VERSION ""

NS_ :

BS_:

BU_: ZD VCU TPMS RESERVED_FRAMES RCM RAC PCU PAS ESP DiagnosticTester CHG CDCM BMS ABS

BO_ 1323 Reserved_148: 8 RESERVED_FRAMES

BO_ 1322 Reserved_147: 8 RESERVED_FRAMES

BO_ 1321 Reserved_146: 8 RESERVED_FRAMES

BO_ 1320 Reserved_145: 8 RESERVED_FRAMES

BO_ 1319 Reserved_144: 8 RESERVED_FRAMES

BO_ 1318 Reserved_143: 8 RESERVED_FRAMES

BO_ 1317 Reserved_142: 8 RESERVED_FRAMES

BO_ 1316 Reserved_141: 8 RESERVED_FRAMES

BO_ 1315 Reserved_140: 8 RESERVED_FRAMES

BO_ 779 Reserved_14: 8 RESERVED_FRAMES

BO_ 1314 Reserved_139: 8 RESERVED_FRAMES

BO_ 1313 Reserved_138: 8 RESERVED_FRAMES

BO_ 1312 Reserved_137: 8 RESERVED_FRAMES

BO_ 1311 Reserved_136: 8 RESERVED_FRAMES

BO_ 1310 Reserved_135: 8 RESERVED_FRAMES

BO_ 1309 Reserved_134: 8 RESERVED_FRAMES

BO_ 1308 Reserved_133: 8 RESERVED_FRAMES

BO_ 1307 Reserved_132: 8 RESERVED_FRAMES

BO_ 1306 Reserved_131: 8 RESERVED_FRAMES

BO_ 1305 Reserved_130: 8 RESERVED_FRAMES

BO_ 1304 Reserved_129: 8 RESERVED_FRAMES

BO_ 1303 Reserved_128: 8 RESERVED_FRAMES

BO_ 1302 Reserved_127: 8 RESERVED_FRAMES

BO_ 1301 Reserved_126: 8 RESERVED_FRAMES

BO_ 1300 Reserved_125: 8 RESERVED_FRAMES

BO_ 1299 Reserved_124: 8 RESERVED_FRAMES

BO_ 1298 Reserved_123: 8 RESERVED_FRAMES

BO_ 1297 Reserved_122: 8 RESERVED_FRAMES

BO_ 1296 Reserved_121: 8 RESERVED_FRAMES

BO_ 1295 Reserved_120: 8 RESERVED_FRAMES

BO_ 1294 Reserved_119: 8 RESERVED_FRAMES

BO_ 1293 Reserved_118: 8 RESERVED_FRAMES

BO_ 1292 Reserved_117: 8 RESERVED_FRAMES

BO_ 1291 Reserved_116: 8 RESERVED_FRAMES

BO_ 1290 Reserved_115: 8 RESERVED_FRAMES

BO_ 1289 Reserved_114: 8 RESERVED_FRAMES

BO_ 1288 Reserved_113: 8 RESERVED_FRAMES

BO_ 1287 Reserved_112: 8 RESERVED_FRAMES

BO_ 1286 Reserved_111: 8 RESERVED_FRAMES

BO_ 1285 Reserved_110: 8 RESERVED_FRAMES

BO_ 1284 Reserved_109: 8 RESERVED_FRAMES

BO_ 1283 Reserved_108: 8 RESERVED_FRAMES

BO_ 1282 Reserved_107: 8 RESERVED_FRAMES

BO_ 1281 Reserved_106: 8 RESERVED_FRAMES

BO_ 1280 Reserved_105: 8 RESERVED_FRAMES

BO_ 1909 Reserved_103: 8 RESERVED_FRAMES

BO_ 1906 Reserved_102: 8 RESERVED_FRAMES

BO_ 146 Reserved_101: 8 RESERVED_FRAMES

BO_ 520 Reserved_100: 8 RESERVED_FRAMES

BO_ 128 Reserved_1: 8 RESERVED_FRAMES

BO_ 1120 RCM_Status: 8 RCM
 SG_ RIL_Request : 39|2@0+ (1,0) [0|3] ""  RAC

BO_ 35 RCM_Event: 1 RCM
 SG_ RCM_FuelCutOff : 6|2@0+ (1,0) [0|3] ""  PCU,RAC,BMS
 SG_ RCM_EventNotification : 7|1@0+ (1,0) [0|1] ""  PCU,BMS,RAC

BO_ 1664 RCM_Diagnostic_Priv: 8 RCM

BO_ 1855 RCM_Diagnostic: 8 RCM

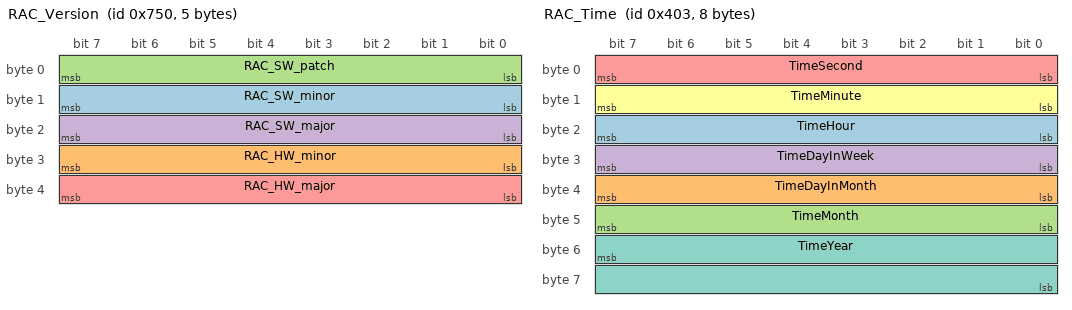
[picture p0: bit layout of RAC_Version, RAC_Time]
BO_ 1872 RAC_Version: 5 RAC
 SG_ RAC_SW_minor : 15|8@0+ (1,0) [0|255] "" Vector__XXX
 SG_ RAC_HW_minor : 31|8@0+ (1,0) [0|255] "" Vector__XXX
 SG_ RAC_SW_patch : 7|8@0+ (1,0) [0|255] "" Vector__XXX
 SG_ RAC_SW_major : 23|8@0+ (1,0) [0|255] "" Vector__XXX
 SG_ RAC_HW_major : 39|8@0+ (1,0) [0|255] "" Vector__XXX

BO_ 1874 RAC_VIN: 8 RAC
 SG_ VIN_Data : 15|48@0+ (1,0) [0|2.8147497671E+014] "" Vector__XXX
 SG_ VIN_Index : 7|8@0+ (1,0) [0|255] "" Vector__XXX

BO_ 1027 RAC_Time: 8 RAC
 SG_ TimeHour : 23|8@0+ (1,0) [0|255] "h" Vector__XXX
 SG_ TimeDayInMonth : 39|8@0+ (1,0) [0|255] "day" Vector__XXX
 SG_ TimeMonth : 47|8@0+ (1,0) [0|255] "Month" Vector__XXX
 SG_ TimeDayInWeek : 31|8@0+ (1,0) [0|255] "" Vector__XXX
 SG_ TimeSecond : 7|8@0+ (1,0) [0|255] "s" Vector__XXX
 SG_ TimeMinute : 15|8@0+ (1,0) [0|255] "min" Vector__XXX
 SG_ TimeYear : 55|16@0+ (1,0) [0|65535] "Year" Vector__XXX

BO_ 1025 RAC_Status: 8 RAC
 SG_ MemoryManagementStatus : 51|1@0+ (1,0) [0|1] "" Vector__XXX
 SG_ AirbagLampDriver : 23|2@0+ (1,0) [0|3] "" Vector__XXX
 SG_ HelpDeskLampStatus : 43|3@0+ (1,0) [0|7] "" Vector__XXX
 SG_ PhoneCallStatus : 36|3@0+ (1,0) [0|7] "" Vector__XXX
 SG_ GPRSStatus : 14|3@0+ (1,0) [0|7] "" Vector__XXX
 SG_ InCommunication : 50|1@0+ (1,0) [0|1] "" Vector__XXX
 SG_ GPSAntennaStatus : 21|2@0+ (1,0) [0|3] "" Vector__XXX
 SG_ CarState : 39|2@0+ (1,0) [0|3] "" Vector__XXX
 SG_ BluetoothConnection : 33|1@0+ (1,0) [0|1] "" Vector__XXX
 SG_ BluetoothStatus : 32|1@0+ (1,0) [0|1] "" Vector__XXX
 SG_ GPSStatus : 19|4@0+ (1,0) [0|15] "" Vector__XXX
 SG_ ContactKey : 0|1@0+ (1,0) [0|1] "" Vector__XXX
 SG_ SIMCardStatus : 8|1@0+ (1,0) [0|1] "" Vector__XXX
 SG_ HelpDeskRequest : 37|1@0+ (1,0) [0|1] "" Vector__XXX
 SG_ GSMStatus : 11|3@0+ (1,0) [0|7] "" Vector__XXX
 SG_ GPSModuleStatus : 53|2@0+ (1,0) [0|3] "" Vector__XXX
 SG_ CSQQuality : 28|5@0+ (1,0) [0|31] "" Vector__XXX
 SG_ ConnectedToServer : 15|1@0+ (1,0) [0|1] "" Vector__XXX
 SG_ AirbagLampStatus : 6|2@0+ (1,0) [0|3] "" Vector__XXX
 SG_ HelpDeskButtonStatus : 1|1@0+ (1,0) [0|1] "" Vector__XXX
 SG_ GSMModuleStatus : 55|2@0+ (1,0) [0|3] "" Vector__XXX
 SG_ AssistNumberProgrammed : 7|1@0+ (1,0) [0|1] "" Vector__XXX
 SG_ EPOStatus : 4|1@0+ (1,0) [0|1] "" Vector__XXX
 SG_ CrashEvent : 3|1@0+ (1,0) [0|1] "" Vector__XXX
 SG_ GPSSatellites : 47|4@0+ (1,0) [0|15] "" Vector__XXX
 SG_ SoundLevel : 31|3@0+ (1,0) [0|7] "" Vector__XXX

BO_ 1030 RAC_SerialNumber2: 8 RAC
 SG_ RACSerialNumber2 : 7|64@0+ (1,0) [0|1.8446744074E+019] "ASCII"  DiagnosticTester

BO_ 1029 RAC_SerialNumber1: 8 RAC
 SG_ RACSerialNumber1 : 7|64@0+ (1,0) [0|1.8446744074E+019] "ASCII"  DiagnosticTester

BO_ 1920 RAC_Phone: 8 RAC
 SG_ PhoneNumber : 15|56@0+ (1,0) [0|7.2057594038E+016] "" Vector__XXX
 SG_ PhoneIndex : 7|8@0+ (1,0) [0|255] "" Vector__XXX

BO_ 1028 RAC_Information: 8 RAC
 SG_ Odometer : 7|32@0+ (1,0) [0|4294967295] "m" Vector__XXX
 SG_ RACSupplyVoltage : 39|16@0+ (1,0) [0|65535] "mV" Vector__XXX

BO_ 1024 RAC_HVAC_Functions: 8 RAC

BO_ 1897 RAC_Diagnostic_2: 8 RAC

BO_ 1904 RAC_Diagnostic: 8 RAC
 SG_ HistoricFlag_SIMNotInserted : 22|1@0+ (1,0) [0|1] ""  DiagnosticTester
 SG_ ErrorFlag_GPSAntennaOC : 9|1@0+ (1,0) [0|1] ""  DiagnosticTester
 SG_ HistoricFlag_WatchdogReboot : 4|1@0+ (1,0) [0|1] ""  DiagnosticTester
 SG_ HistoricFlag_GPSNotResponding : 18|1@0+ (1,0) [0|1] ""  DiagnosticTester
 SG_ ErrorFlag_SIMNotInserted : 23|1@0+ (1,0) [0|1] ""  DiagnosticTester
 SG_ ErrorFlag_GPSAntennaSCGND : 17|1@0+ (1,0) [0|1] ""  DiagnosticTester
 SG_ HistoricFlag_GSMNotResponding : 2|1@0+ (1,0) [0|1] ""  DiagnosticTester
 SG_ HistoricFlag_FlashMemoryError : 6|1@0+ (1,0) [0|1] ""  DiagnosticTester
 SG_ ErrorFlag_VeryLowBattery : 25|1@0+ (1,0) [0|1] "" Vector__XXX
 SG_ ErrorFlag_HelpdeskNotPrg : 15|1@0+ (1,0) [0|1] ""  DiagnosticTester
 SG_ ErrorFlag_SIMRefused : 21|1@0+ (1,0) [0|1] ""  DiagnosticTester
 SG_ ErrorFlag_PINError : 1|1@0+ (1,0) [0|1] ""  DiagnosticTester
 SG_ ErrorFlag_FlashMemoryError : 7|1@0+ (1,0) [0|1] ""  DiagnosticTester
 SG_ ErrorFlag_LowBattery : 29|1@0+ (1,0) [0|1] "" Vector__XXX
 SG_ HistoricFlag_LastDownloadFailed : 26|1@0+ (1,0) [0|1] "" Vector__XXX
 SG_ ErrorFlag_WatchdogReboot : 5|1@0+ (1,0) [0|1] ""  DiagnosticTester
 SG_ HistoricFlag_PINError : 0|1@0+ (1,0) [0|1] ""  DiagnosticTester
 SG_ ErrorFlag_GPSNotResponding : 19|1@0+ (1,0) [0|1] ""  DiagnosticTester
 SG_ HistoricFlag_VeryLowBattery : 24|1@0+ (1,0) [0|1] "" Vector__XXX
 SG_ HistoricFlag_LowBattery : 28|1@0+ (1,0) [0|1] "" Vector__XXX
 SG_ HistoricFlag_BlueNotResponding : 30|1@0+ (1,0) [0|1] ""  DiagnosticTester
 SG_ ErrorFlag_BlueNotResponding : 31|1@0+ (1,0) [0|1] ""  DiagnosticTester
 SG_ ErrorFlag_LastDownloadFailed : 27|1@0+ (1,0) [0|1] "" Vector__XXX
 SG_ HistoricFlag_SIMRefused : 20|1@0+ (1,0) [0|1] ""  DiagnosticTester
 SG_ ErrorFlag_GSMNotResponding : 3|1@0+ (1,0) [0|1] ""  DiagnosticTester
 SG_ HistoricFlag_GPSAntennaOC : 8|1@0+ (1,0) [0|1] ""  DiagnosticTester
 SG_ HistoricFlag_GPSAntennaSCGND : 16|1@0+ (1,0) [0|1] ""  DiagnosticTester
 SG_ HistoricFlag_HelpDeskNotPrg : 14|1@0+ (1,0) [0|1] ""  DiagnosticTester

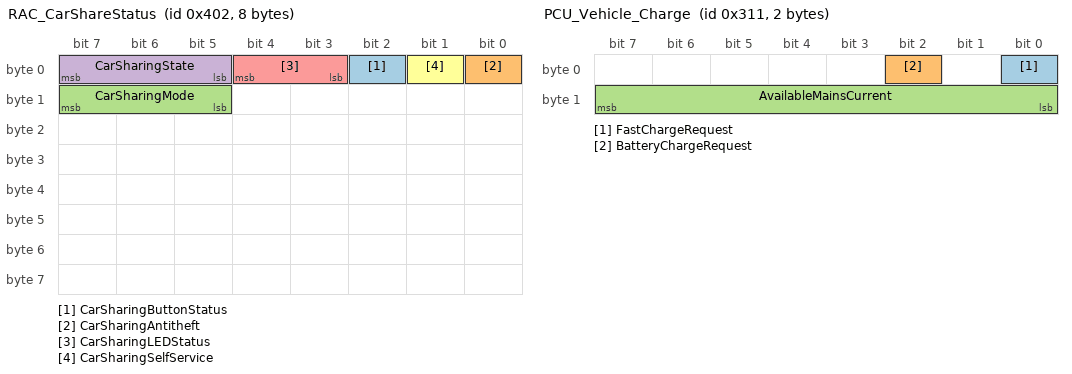
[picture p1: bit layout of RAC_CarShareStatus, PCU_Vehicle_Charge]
BO_ 1026 RAC_CarShareStatus: 8 RAC
 SG_ CarSharingButtonStatus : 2|1@0+ (1,0) [0|1] "" Vector__XXX
 SG_ CarSharingAntitheft : 0|1@0+ (1,0) [0|1] "" Vector__XXX
 SG_ CarSharingMode : 15|3@0+ (1,0) [0|7] "" Vector__XXX
 SG_ CarSharingState : 7|3@0+ (1,0) [0|7] "" Vector__XXX
 SG_ CarSharingLEDStatus : 4|2@0+ (1,0) [0|3] "" Vector__XXX
 SG_ CarSharingSelfService : 1|1@0+ (1,0) [0|1] "" Vector__XXX

BO_ 785 PCU_Vehicle_Charge: 2 PCU
 SG_ FastChargeRequest : 0|1@0+ (1,0) [0|1] ""  BMS
 SG_ BatteryChargeRequest : 2|1@0+ (1,0) [0|1] ""  BMS
 SG_ AvailableMainsCurrent : 15|8@0+ (0.2,0) [0|51] "A"  BMS

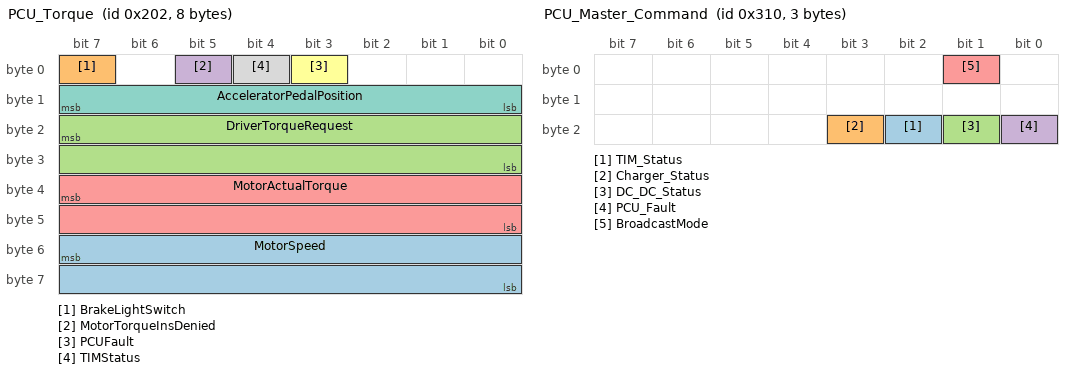
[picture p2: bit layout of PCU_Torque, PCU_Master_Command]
BO_ 514 PCU_Torque: 8 PCU
 SG_ MotorSpeed : 55|16@0- (1,0) [-32768|32767] "rpm"  ESP
 SG_ BrakeLightSwitch : 7|1@0+ (1,0) [0|1] ""  ESP
 SG_ DriverTorqueRequest : 23|16@0- (0.1,0) [-3276.8|3276.7] "Nm"  ESP
 SG_ MotorTorqueInsDenied : 5|1@0+ (1,0) [0|1] ""  ESP
 SG_ MotorActualTorque : 39|16@0- (0.1,0) [-3276.8|3276.7] "Nm"  ESP
 SG_ PCUFault : 3|1@0+ (1,0) [0|1] ""  ESP
 SG_ AcceleratorPedalPosition : 15|8@0+ (0.5,0) [0|127.5] "%"  ESP
 SG_ TIMStatus : 4|1@0+ (1,0) [0|1] ""  ESP

BO_ 595 PCU_Security_ID_2: 8 PCU
 SG_ SecurityID_2 : 7|64@0+ (1,0) [0|1.8446744074E+019] ""  VCU

BO_ 594 PCU_Security_ID_1: 8 PCU
 SG_ SecurityID_1 : 7|64@0+ (1,0) [0|1.8446744074E+019] ""  VCU

BO_ 784 PCU_Master_Command: 3 PCU
 SG_ TIM_Status : 18|1@0+ (1,0) [0|1] ""  BMS
 SG_ Charger_Status : 19|1@0+ (1,0) [0|1] ""  BMS
 SG_ DC_DC_Status : 17|1@0+ (1,0) [0|1] ""  BMS
 SG_ PCU_Fault : 16|1@0+ (1,0) [0|1] ""  BMS
 SG_ BroadcastMode : 1|1@0+ (1,0) [0|1] ""  BMS

BO_ 849 PCU_LogInResponse: 7 PCU
 SG_ ChargerRequest : 7|48@0+ (1,0) [0|2.8147497671E+014] ""  CHG
 SG_ ChargerAssignedID : 55|8@0+ (1,0) [0|255] ""  CHG

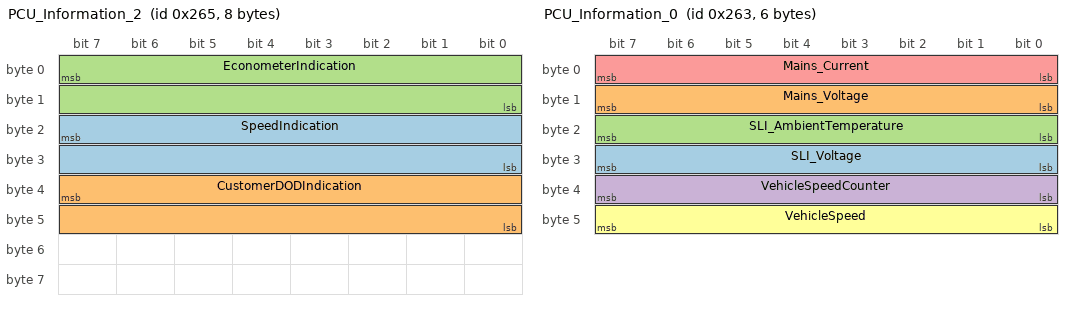
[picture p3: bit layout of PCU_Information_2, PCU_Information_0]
BO_ 613 PCU_Information_2: 8 PCU
 SG_ SpeedIndication : 23|16@0+ (0.1,0) [0|6553.5] "km/h"  VCU
 SG_ CustomerDODIndication : 39|16@0+ (0.1,0) [0|6553.5] "%"  VCU
 SG_ EconometerIndication : 7|16@0- (0.1,0) [-3276.8|3276.7] "%"  VCU

BO_ 612 PCU_Information_1: 8 PCU
 SG_ PASEnable : 0|1@0+ (1,0) [0|1] ""  RAC,VCU,PAS
 SG_ ESPIndication : 55|2@0+ (1,0) [0|3] "" Vector__XXX
 SG_ PowerLimitIndication : 19|2@0+ (1,0) [0|3] ""  VCU
 SG_ EconomyIndication : 25|2@0+ (1,0) [0|3] ""  VCU
 SG_ PCUESPSoftware : 44|1@0+ (1,0) [0|1] "" Vector__XXX
 SG_ ABSWarningIndication : 23|2@0+ (1,0) [0|3] ""  VCU
 SG_ ElectricHzIndication : 11|2@0+ (1,0) [0|3] ""  VCU
 SG_ BrakeWarningIndication : 21|2@0+ (1,0) [0|3] ""  VCU
 SG_ OvertempIndication : 9|2@0+ (1,0) [0|3] ""  VCU
 SG_ NeutralIndication : 37|2@0+ (1,0) [0|3] ""  VCU
 SG_ MILIndication : 13|2@0+ (1,0) [0|3] ""  VCU
 SG_ PowertrainGeneration : 43|4@0+ (1,0) [0|15] "" Vector__XXX
 SG_ ChargingIndication : 29|2@0+ (1,0) [0|3] ""  VCU
 SG_ AuxiliaryBatteryLowIndication : 17|2@0+ (1,0) [0|3] ""  VCU
 SG_ DriveEnableIndication : 31|2@0+ (1,0) [0|3] ""  VCU
 SG_ PCUPTCReady : 53|1@0+ (1,0) [0|1] "" Vector__XXX
 SG_ OnPlugIndication : 27|2@0+ (1,0) [0|3] ""  VCU
 SG_ GearPosition : 47|3@0+ (1,0) [0|7] ""  VCU
 SG_ ParkIndication : 33|2@0+ (1,0) [0|3] ""  VCU
 SG_ ReverseIndication : 35|2@0+ (1,0) [0|3] ""  VCU
 SG_ LowSOCIndication : 15|2@0+ (1,0) [0|3] ""  VCU
 SG_ PilotSignalPresent : 1|1@0+ (1,0) [0|1] ""  VCU,PAS,RAC
 SG_ DriveIndication : 39|2@0+ (1,0) [0|3] ""  VCU

BO_ 611 PCU_Information_0: 6 PCU
 SG_ SLI_Voltage : 31|8@0+ (0.1,0) [0|25.5] "VDC"  BMS
 SG_ Mains_Voltage : 15|8@0+ (1,0) [0|255] "V AC rms"  BMS,PAS,RAC
 SG_ SLI_AmbientTemperature : 23|8@0- (0.5,0) [-64|63.5] "deg C"  RAC,PAS,TPMS,BMS
 SG_ VehicleSpeedCounter : 39|8@0+ (1,0) [0|255] ""  BMS
 SG_ Mains_Current : 7|8@0+ (0.2,0) [0|51] "A"  PAS,BMS,RAC
 SG_ VehicleSpeed : 47|8@0+ (0.5,0) [0|127.5] "kph / km/h"  RAC,BMS,PAS,TPMS

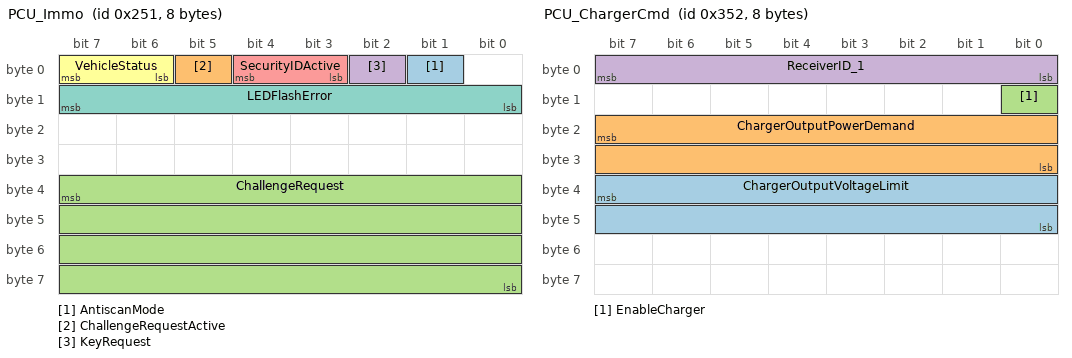
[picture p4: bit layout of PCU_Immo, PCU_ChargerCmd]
BO_ 593 PCU_Immo: 8 PCU
 SG_ AntiscanMode : 1|1@0+ (1,0) [0|1] "" Vector__XXX
 SG_ ChallengeRequestActive : 5|1@0+ (1,0) [0|1] ""  VCU
 SG_ ChallengeRequest : 39|32@0+ (1,0) [0|4294967295] ""  VCU
 SG_ KeyRequest : 2|1@0+ (1,0) [0|1] "" Vector__XXX
 SG_ SecurityIDActive : 4|2@0+ (1,0) [0|3] ""  VCU
 SG_ VehicleStatus : 7|2@0+ (1,0) [0|3] ""  VCU
 SG_ LEDFlashError : 15|8@0+ (1,0) [0|255] ""  VCU

BO_ 1883 PCU_Diagnostic: 8 PCU

BO_ 850 PCU_ChargerCmd: 8 PCU
 SG_ ChargerOutputVoltageLimit : 39|16@0+ (0.1,0) [0|6553.5] "V"  CHG
 SG_ ChargerOutputPowerDemand : 23|16@0+ (0.1,0) [0|100] "%"  CHG
 SG_ EnableCharger : 8|1@0+ (1,0) [0|1] ""  CHG
 SG_ ReceiverID_1 : 7|8@0+ (1,0) [0|255] ""  CHG

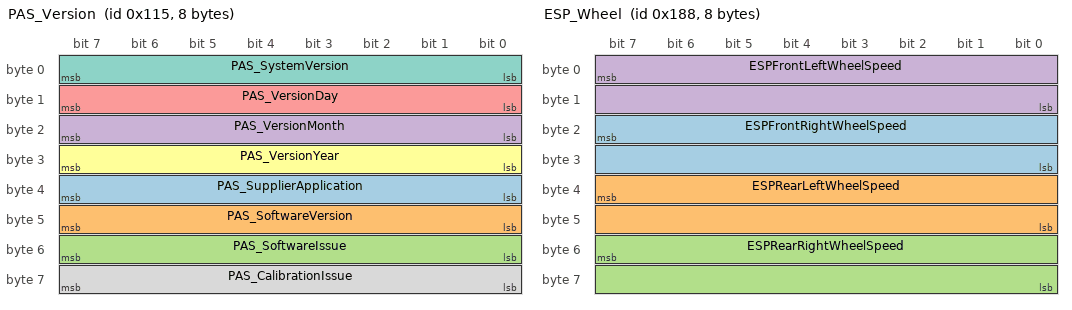
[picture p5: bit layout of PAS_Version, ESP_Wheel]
BO_ 277 PAS_Version: 8 PAS
 SG_ PAS_SupplierApplication : 39|8@0+ (1,0) [0|255] ""  DiagnosticTester
 SG_ PAS_SoftwareVersion : 47|8@0+ (1,0) [0|255] ""  DiagnosticTester
 SG_ PAS_SoftwareIssue : 55|8@0+ (1,0) [0|255] ""  DiagnosticTester
 SG_ PAS_VersionMonth : 23|8@0+ (1,0) [0|12] ""  DiagnosticTester
 SG_ PAS_VersionDay : 15|8@0+ (1,0) [0|31] ""  DiagnosticTester
 SG_ PAS_VersionYear : 31|8@0+ (1,0) [0|99] ""  DiagnosticTester
 SG_ PAS_SystemVersion : 7|8@0+ (1,0) [0|255] ""  DiagnosticTester
 SG_ PAS_CalibrationIssue : 63|8@0+ (1,0) [0|255] ""  DiagnosticTester

BO_ 1173 PAS_Status: 2 PAS
 SG_ PAS_Status : 15|8@0+ (1,0) [0|255] ""  PCU

BO_ 1685 PAS_Diagnostic: 8 PAS

BO_ 392 ESP_Wheel: 8 ESP
 SG_ ESPFrontRightWheelSpeed : 23|16@0+ (0.0625,0) [0|4095.9375] "km/h" Vector__XXX
 SG_ ESPRearLeftWheelSpeed : 39|16@0+ (0.0625,0) [0|4095.9375] "km/h" Vector__XXX
 SG_ ESPRearRightWheelSpeed : 55|16@0+ (0.0625,0) [0|4095.9375] "km/h" Vector__XXX
 SG_ ESPFrontLeftWheelSpeed : 7|16@0+ (0.0625,0) [0|4095.9375] "km/h" Vector__XXX

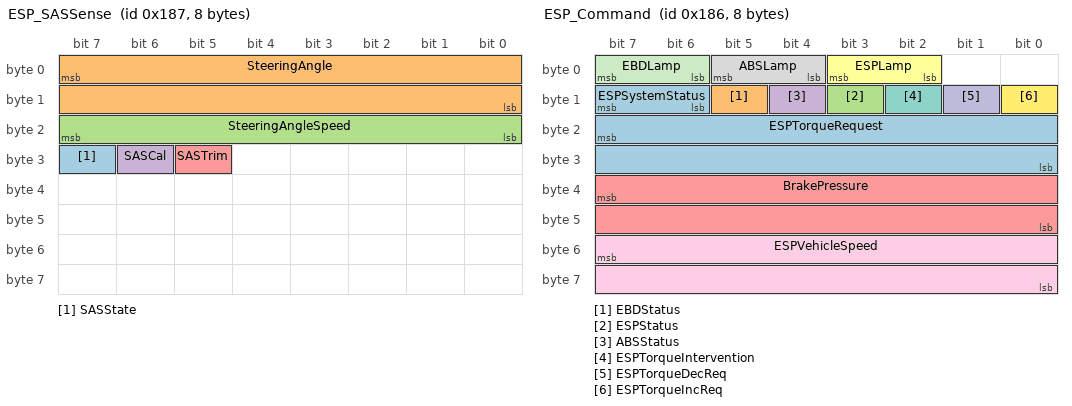
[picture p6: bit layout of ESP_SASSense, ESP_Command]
BO_ 391 ESP_SASSense: 8 ESP
 SG_ SASState : 31|1@0+ (1,0) [0|1] "" Vector__XXX
 SG_ SteeringAngle : 7|16@0- (0.1,0) [-3276.8|3276.7] "deg" Vector__XXX
 SG_ SteeringAngleSpeed : 23|8@0+ (4,0) [0|1020] "deg/s" Vector__XXX
 SG_ SASCal : 30|1@0+ (1,0) [0|1] "" Vector__XXX
 SG_ SASTrim : 29|1@0+ (1,0) [0|1] "" Vector__XXX

BO_ 390 ESP_Command: 8 ESP
 SG_ ESPSystemStatus : 15|2@0+ (1,0) [0|3] ""  PCU
 SG_ EBDStatus : 13|1@0+ (1,0) [0|1] ""  PCU
 SG_ ESPStatus : 11|1@0+ (1,0) [0|1] ""  PCU
 SG_ ABSStatus : 12|1@0+ (1,0) [0|1] ""  PCU
 SG_ BrakePressure : 39|16@0+ (0.0625,0) [0|4095.9375] "bar"  PCU
 SG_ ESPLamp : 3|2@0+ (1,0) [0|3] ""  PCU
 SG_ ESPTorqueIntervention : 10|1@0+ (1,0) [0|1] ""  PCU
 SG_ ABSLamp : 5|2@0+ (1,0) [0|3] ""  PCU
 SG_ ESPVehicleSpeed : 55|16@0+ (0.0625,0) [0|4095.9375] "km/h"  PCU
 SG_ ESPTorqueDecReq : 9|1@0+ (1,0) [0|1] ""  PCU
 SG_ EBDLamp : 7|2@0+ (1,0) [0|3] ""  PCU
 SG_ ESPTorqueIncReq : 8|1@0+ (1,0) [0|1] ""  PCU
 SG_ ESPTorqueRequest : 23|16@0- (0.1,0) [-3276.8|3276.7] "Nm"  PCU

BO_ 2000 Diagnostic_VCU: 8 DiagnosticTester

BO_ 1921 Diagnostic_TPMS: 8 DiagnosticTester

BO_ 1665 Diagnostic_RCM_Priv: 8 DiagnosticTester

BO_ 1847 Diagnostic_RCM: 8 DiagnosticTester

BO_ 1873 Diagnostic_RAC_Configuration: 8 DiagnosticTester

BO_ 1905 Diagnostic_RAC: 8 DiagnosticTester

BO_ 1875 Diagnostic_PCU: 8 DiagnosticTester

BO_ 1717 Diagnostic_PAS: 8 DiagnosticTester

BO_ 1910 Diagnostic_CDCM: 8 DiagnosticTester

BO_ 1861 Diagnostic_BMS: 8 DiagnosticTester

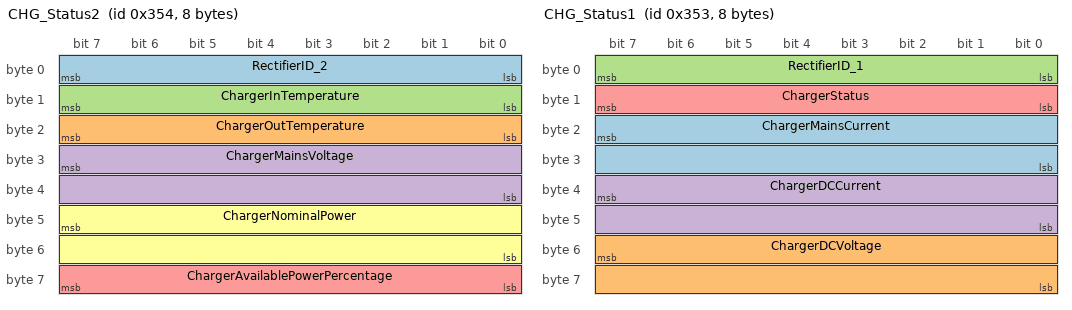
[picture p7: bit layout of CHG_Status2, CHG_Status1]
BO_ 852 CHG_Status2: 8 CHG
 SG_ RectifierID_2 : 7|8@0+ (1,0) [0|255] ""  PCU
 SG_ ChargerOutTemperature : 23|8@0- (1,0) [-128|127] "deg C"  PCU
 SG_ ChargerInTemperature : 15|8@0- (1,0) [-128|127] "deg C"  PCU
 SG_ ChargerMainsVoltage : 31|16@0+ (1,0) [0|65535] "V rms"  PCU
 SG_ ChargerAvailablePowerPercentage : 63|8@0+ (0.5,0) [0|127.5] "%" Vector__XXX
 SG_ ChargerNominalPower : 47|16@0+ (1,0) [0|65535] "W" Vector__XXX

BO_ 851 CHG_Status1: 8 CHG
 SG_ ChargerMainsCurrent : 23|16@0+ (0.2,0) [0|13107] "A rms"  PCU
 SG_ ChargerDCVoltage : 55|16@0+ (0.1,0) [0|6553.5] "V"  PCU
 SG_ RectifierID_1 : 7|8@0+ (1,0) [0|255] ""  PCU
 SG_ ChargerDCCurrent : 39|16@0- (0.1,0) [-3276.8|3276.7] "A"  PCU
 SG_ ChargerStatus : 15|8@0+ (1,0) [0|255] ""  PCU

BO_ 1640 CHG_Secondary_Download: 8 Vector__XXX

BO_ 1639 CHG_Primary_Download: 8 Vector__XXX

BO_ 848 CHG_LogInRequest: 6 CHG
 SG_ LogInRequest : 7|48@0+ (1,0) [0|2.8147497671E+014] ""  PCU

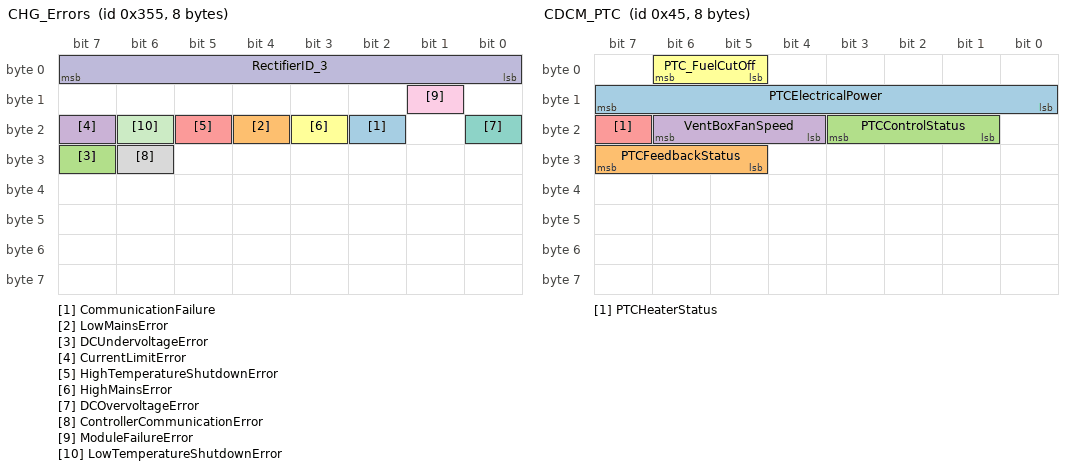
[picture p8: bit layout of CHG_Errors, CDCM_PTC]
BO_ 853 CHG_Errors: 8 CHG
 SG_ CommunicationFailure : 18|1@0+ (1,0) [0|1] ""  PCU
 SG_ LowMainsError : 20|1@0+ (1,0) [0|1] ""  PCU
 SG_ DCUndervoltageError : 31|1@0+ (1,0) [0|1] ""  PCU
 SG_ CurrentLimitError : 23|1@0+ (1,0) [0|1] ""  PCU
 SG_ HighTemperatureShutdownError : 21|1@0+ (1,0) [0|1] ""  PCU
 SG_ HighMainsError : 19|1@0+ (1,0) [0|1] ""  PCU
 SG_ DCOvervoltageError : 16|1@0+ (1,0) [0|1] ""  PCU
 SG_ ControllerCommunicationError : 30|1@0+ (1,0) [0|1] ""  PCU
 SG_ ModuleFailureError : 9|1@0+ (1,0) [0|1] ""  PCU
 SG_ RectifierID_3 : 7|8@0+ (1,0) [0|255] ""  PCU
 SG_ LowTemperatureShutdownError : 22|1@0+ (1,0) [0|1] ""  PCU

BO_ 1032 CDCM_Status: 8 CDCM
 SG_ CDCMFrontDemistSwitch : 27|1@0+ (1,0) [0|1] "" Vector__XXX
 SG_ CDCMRearDemistSwitch : 24|1@0+ (1,0) [0|1] "" Vector__XXX
 SG_ CDCMHWVersion : 15|8@0+ (1,0) [0|255] "" Vector__XXX
 SG_ ACPresent : 23|1@0+ (1,0) [0|1] "" Vector__XXX
 SG_ CDCMKeyRun : 28|1@0+ (1,0) [0|1] "" Vector__XXX
 SG_ CDCMWakeUp : 30|1@0+ (1,0) [0|1] "" Vector__XXX
 SG_ CDCMSWVersion : 7|8@0+ (1,0) [0|255] "" Vector__XXX
 SG_ CDCM12VSupply : 55|8@0+ (0.1,0) [0|25.5] "VDC" Vector__XXX
 SG_ CDCMHeaterFault : 31|1@0+ (1,0) [0|1] "" Vector__XXX
 SG_ CDCMHVRequest : 38|1@0+ (1,0) [0|1] "" Vector__XXX
 SG_ CDCMFrontDemist1 : 35|1@0+ (1,0) [0|1] "" Vector__XXX
 SG_ CDCMCondenserFan : 34|1@0+ (1,0) [0|1] "" Vector__XXX
 SG_ EvaporatorTemperature : 47|8@0- (0.8,0) [-102.4|101.6] "deg C" Vector__XXX
 SG_ CDCMHeaterEnable : 33|1@0+ (1,0) [0|1] "" Vector__XXX
 SG_ CDCMInverterSupply : 39|1@0+ (1,0) [0|1] "" Vector__XXX
 SG_ CDCMForcedBlower : 37|1@0+ (1,0) [0|1] "" Vector__XXX
 SG_ CDCMFrontDemist2 : 36|1@0+ (1,0) [0|1] "" Vector__XXX
 SG_ HeaterKnobPosition : 63|8@0+ (1,0) [0|255] "%" Vector__XXX
 SG_ CDCMRearDemist : 32|1@0+ (1,0) [0|1] "" Vector__XXX
 SG_ CDCMOperationState : 19|4@0+ (1,0) [0|15] "" Vector__XXX
 SG_ CDCMACRequest : 29|1@0+ (1,0) [0|1] "" Vector__XXX

BO_ 69 CDCM_PTC: 8 CDCM
 SG_ PTCElectricalPower : 15|8@0+ (0.1,0) [0|25.5] "kW" Vector__XXX
 SG_ PTCFeedbackStatus : 31|3@0+ (1,0) [0|7] "" Vector__XXX
 SG_ PTCControlStatus : 19|3@0+ (1,0) [0|7] "" Vector__XXX
 SG_ VentBoxFanSpeed : 22|3@0+ (1,0) [0|7] "" Vector__XXX
 SG_ PTCHeaterStatus : 23|1@0+ (1,0) [0|0] "" Vector__XXX
 SG_ PTC_FuelCutOff : 6|2@0+ (1,0) [0|3] ""  BMS,PCU

BO_ 1033 CDCM_Error: 8 CDCM
 SG_ KnobPositionTooHigh : 19|1@0+ (1,0) [0|1] "" Vector__XXX
 SG_ CondenserFanOC : 2|1@0+ (1,0) [0|1] "" Vector__XXX
 SG_ PTCCommunicationBroken : 43|1@0+ (1,0) [0|1] "" Vector__XXX
 SG_ RearDemistSC : 8|1@0+ (1,0) [0|1] "" Vector__XXX
 SG_ PTCHVMissing : 44|1@0+ (1,0) [0|1] "" Vector__XXX
 SG_ HVrequestSC : 14|1@0+ (1,0) [0|1] "" Vector__XXX
 SG_ FrontDemist2OC : 4|1@0+ (1,0) [0|1] "" Vector__XXX
 SG_ FluidHeaterFaultLineOld : 23|1@0+ (1,0) [0|1] "" Vector__XXX
 SG_ ClimateCANTimeout : 32|1@0+ (1,0) [0|1] "" Vector__XXX
 SG_ KnobPositionTooLow : 18|1@0+ (1,0) [0|1] "" Vector__XXX
 SG_ PTCOtherError : 42|1@0+ (1,0) [0|1] "" Vector__XXX
 SG_ HeaterEnableOC : 1|1@0+ (1,0) [0|1] "" Vector__XXX
 SG_ HeaterEnableSC : 9|1@0+ (1,0) [0|1] "" Vector__XXX
 SG_ CondenserFanSC : 10|1@0+ (1,0) [0|1] "" Vector__XXX
 SG_ ForcedBlowerOC : 5|1@0+ (1,0) [0|1] "" Vector__XXX
 SG_ InverterSupplyOC : 7|1@0+ (1,0) [0|1] "" Vector__XXX
 SG_ FrontDemist1SC : 11|1@0+ (1,0) [0|1] "" Vector__XXX
 SG_ BMSSWNotReady : 45|1@0+ (1,0) [0|1] "" Vector__XXX
 SG_ ForcedBlowerSC : 13|1@0+ (1,0) [0|1] "" Vector__XXX
 SG_ RearDemistOC : 0|1@0+ (1,0) [0|1] "" Vector__XXX
 SG_ TemperatureSensorSignalTooLow : 16|1@0+ (1,0) [0|1] "" Vector__XXX
 SG_ TemperatureSensorSignalTooHigh : 17|1@0+ (1,0) [0|1] "" Vector__XXX
 SG_ InverterSupplySC : 15|1@0+ (1,0) [0|1] "" Vector__XXX
 SG_ FrontDemist2SC : 12|1@0+ (1,0) [0|1] "" Vector__XXX
 SG_ FrontDemist1OC : 3|1@0+ (1,0) [0|1] "" Vector__XXX
 SG_ FluidHeaterFaultLineCurrent : 22|1@0+ (1,0) [0|1] "" Vector__XXX
 SG_ PCUSWNotReady : 47|1@0+ (1,0) [0|1] "" Vector__XXX
 SG_ VCUSWNotReady : 46|1@0+ (1,0) [0|1] "" Vector__XXX
 SG_ HVRequestOC : 6|1@0+ (1,0) [0|1] "" Vector__XXX

BO_ 1918 CDCM_Diagnostic_Copy_1: 8 CDCM

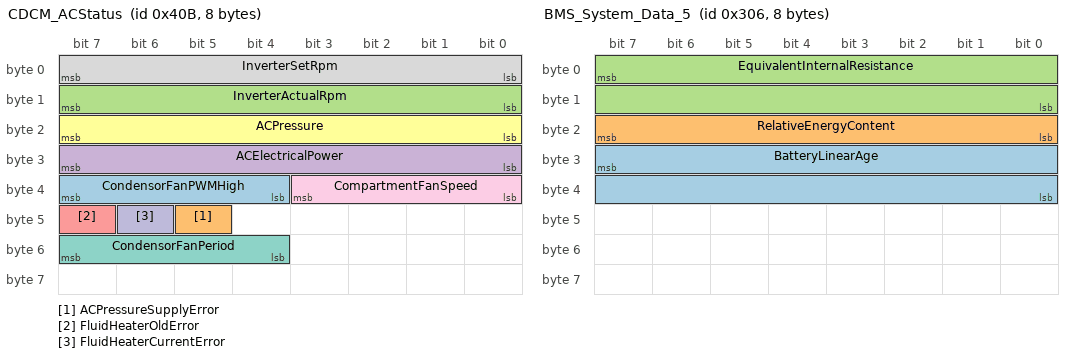
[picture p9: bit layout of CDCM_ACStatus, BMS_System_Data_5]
BO_ 1035 CDCM_ACStatus: 8 CDCM
 SG_ CondensorFanPWMHigh : 39|4@0+ (5,0) [0|75] "ms" Vector__XXX
 SG_ ACPressureSupplyError : 45|1@0+ (1,0) [0|1] "" Vector__XXX
 SG_ InverterActualRpm : 15|8@0+ (60,0) [0|15300] "rpm" Vector__XXX
 SG_ ACElectricalPower : 31|8@0+ (0.1,0) [0|25.5] "kW" Vector__XXX
 SG_ FluidHeaterOldError : 47|1@0+ (1,0) [0|1] "" Vector__XXX
 SG_ ACPressure : 23|8@0+ (1,0) [0|35] "bar" Vector__XXX
 SG_ CondensorFanPeriod : 55|4@0+ (5,0) [0|75] "ms" Vector__XXX
 SG_ InverterSetRpm : 7|8@0+ (60,0) [0|15300] "rpm" Vector__XXX
 SG_ CompartmentFanSpeed : 35|4@0+ (1,0) [0|15] "" Vector__XXX
 SG_ FluidHeaterCurrentError : 46|1@0+ (1,0) [0|1] "" Vector__XXX

BO_ 51 CCP_VCU_DTO: 8 Vector__XXX

BO_ 1957 CCP_VCU_DAC2: 8 Vector__XXX

BO_ 1956 CCP_VCU_DAC1: 8 Vector__XXX

BO_ 1955 CCP_VCU_DAC0: 8 Vector__XXX

BO_ 50 CCP_VCU_CRO: 8 Vector__XXX

BO_ 55 CCP_PCU_DTO: 8 Vector__XXX

BO_ 1963 CCP_PCU_DAC2: 8 Vector__XXX

BO_ 1962 CCP_PCU_DAC1: 8 Vector__XXX

BO_ 1961 CCP_PCU_DAC0: 8 Vector__XXX

BO_ 54 CCP_PCU_CRO: 8 Vector__XXX

BO_ 53 CCP_CHG_DTO: 8 Vector__XXX

BO_ 1960 CCP_CHG_DAC2: 8 Vector__XXX

BO_ 1959 CCP_CHG_DAC1: 8 Vector__XXX

BO_ 1958 CCP_CHG_DAC0: 8 Vector__XXX

BO_ 52 CCP_CHG_CRO: 8 Vector__XXX

BO_ 49 CCP_CDCM_DTO: 8 Vector__XXX

BO_ 1954 CCP_CDCM_DAC2: 8 Vector__XXX

BO_ 1953 CCP_CDCM_DAC1: 8 Vector__XXX

BO_ 1952 CCP_CDCM_DAC0: 8 Vector__XXX

BO_ 48 CCP_CDCM_CRO: 8 Vector__XXX

BO_ 57 CCP_BMS_DTO: 8 Vector__XXX

BO_ 1966 CCP_BMS_DAC2: 8 Vector__XXX

BO_ 1965 CCP_BMS_DAC1: 8 Vector__XXX

BO_ 1964 CCP_BMS_DAC0: 8 Vector__XXX

BO_ 56 CCP_BMS_CRO: 8 Vector__XXX

BO_ 774 BMS_System_Data_5: 8 BMS
 SG_ BatteryLinearAge : 31|16@0+ (1,0) [0|65535] "" Vector__XXX
 SG_ RelativeEnergyContent : 23|8@0+ (0.5,0) [0|100] "%" Vector__XXX
 SG_ EquivalentInternalResistance : 7|16@0+ (0.001,0) [0|65.535] "Ohms" Vector__XXX

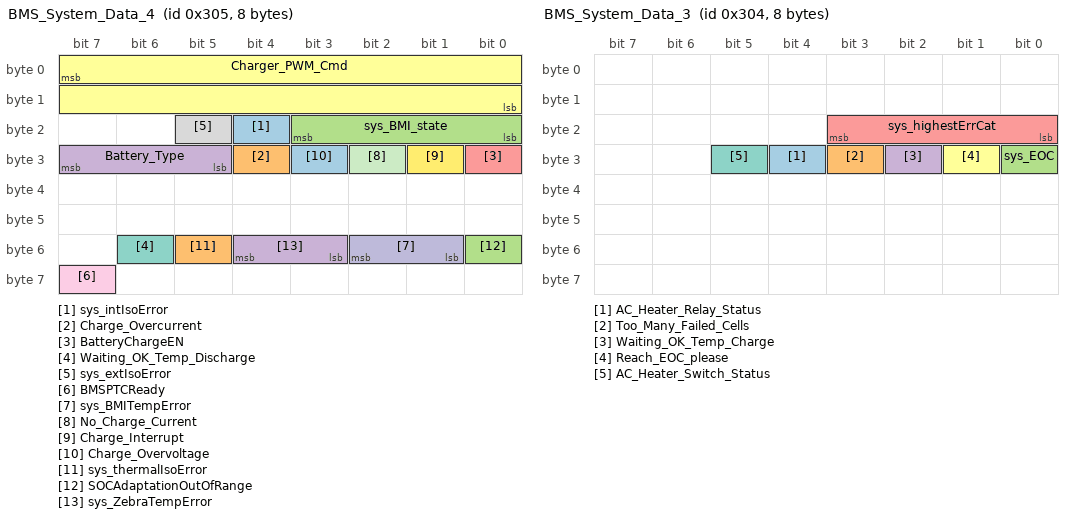
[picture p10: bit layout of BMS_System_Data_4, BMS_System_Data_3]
BO_ 773 BMS_System_Data_4: 8 BMS
 SG_ sys_intIsoError : 20|1@0+ (1,0) [0|1] ""  PCU
 SG_ Charge_Overcurrent : 28|1@0+ (1,0) [0|1] "" Vector__XXX
 SG_ sys_BMI_state : 19|4@0+ (1,0) [0|15] "" Vector__XXX
 SG_ Battery_Type : 31|3@0+ (1,0) [0|7] ""  PCU
 SG_ BatteryChargeEN : 24|1@0+ (1,0) [0|1] ""  PCU
 SG_ Charger_PWM_Cmd : 7|16@0+ (0.1,0) [0|100] "%"  PCU
 SG_ Waiting_OK_Temp_Discharge : 54|1@0+ (1,0) [0|1] ""  PCU
 SG_ sys_extIsoError : 21|1@0+ (1,0) [0|1] ""  PCU
 SG_ BMSPTCReady : 63|1@0+ (1,0) [0|1] "" Vector__XXX
 SG_ sys_BMITempError : 50|2@0+ (1,0) [0|3] ""  PCU
 SG_ No_Charge_Current : 26|1@0+ (1,0) [0|1] ""  PCU
 SG_ Charge_Interrupt : 25|1@0+ (1,0) [0|1] "" Vector__XXX
 SG_ Charge_Overvoltage : 27|1@0+ (1,0) [0|1] "" Vector__XXX
 SG_ sys_thermalIsoError : 53|1@0+ (1,0) [0|1] ""  PCU
 SG_ SOCAdaptationOutOfRange : 48|1@0+ (1,0) [0|1] "" Vector__XXX
 SG_ sys_ZebraTempError : 52|2@0+ (1,0) [0|3] ""  PCU

BO_ 772 BMS_System_Data_3: 8 BMS
 SG_ AC_Heater_Relay_Status : 28|1@0+ (1,0) [0|1] ""  PCU
 SG_ Too_Many_Failed_Cells : 27|1@0+ (1,0) [0|1] ""  PCU
 SG_ sys_EOC : 24|1@0+ (1,0) [0|1] ""  PCU
 SG_ Waiting_OK_Temp_Charge : 26|1@0+ (1,0) [0|1] ""  PCU
 SG_ sys_highestErrCat : 19|4@0+ (1,0) [0|15] ""  PCU
 SG_ Reach_EOC_please : 25|1@0+ (1,0) [0|1] ""  PCU
 SG_ AC_Heater_Switch_Status : 29|1@0+ (1,0) [0|1] ""  PCU

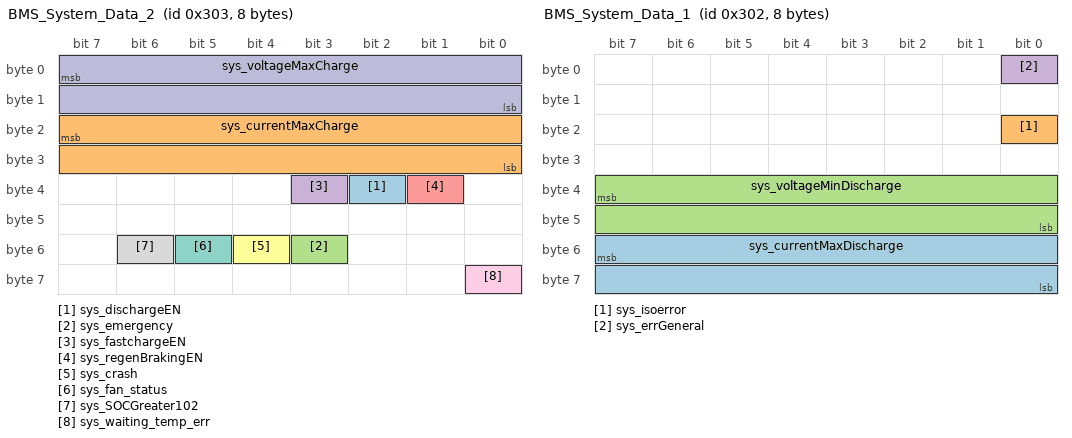
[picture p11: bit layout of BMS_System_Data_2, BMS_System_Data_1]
BO_ 771 BMS_System_Data_2: 8 BMS
 SG_ sys_dischargeEN : 34|1@0+ (1,0) [0|1] ""  PCU
 SG_ sys_currentMaxCharge : 23|16@0+ (0.1,0) [0|6553.5] "A"  PCU
 SG_ sys_emergency : 51|1@0+ (1,0) [0|1] ""  PCU
 SG_ sys_fastchargeEN : 35|1@0+ (1,0) [0|1] ""  PCU
 SG_ sys_regenBrakingEN : 33|1@0+ (1,0) [0|1] ""  PCU
 SG_ sys_crash : 52|1@0+ (1,0) [0|1] ""  PCU
 SG_ sys_fan_status : 53|1@0+ (1,0) [0|1] ""  PCU
 SG_ sys_SOCGreater102 : 54|1@0+ (1,0) [0|1] ""  PCU
 SG_ sys_waiting_temp_err : 56|1@0+ (1,0) [0|1] ""  PCU
 SG_ sys_voltageMaxCharge : 7|16@0+ (0.1,0) [0|6553.5] "V"  PCU

BO_ 770 BMS_System_Data_1: 8 BMS
 SG_ sys_currentMaxDischarge : 55|16@0+ (0.1,0) [0|6553.5] "A"  PCU
 SG_ sys_isoerror : 16|1@0+ (1,0) [0|1] ""  PCU
 SG_ sys_voltageMinDischarge : 39|16@0+ (0.1,0) [0|6553.5] "V"  PCU
 SG_ sys_errGeneral : 0|1@0+ (1,0) [0|1] ""  PCU

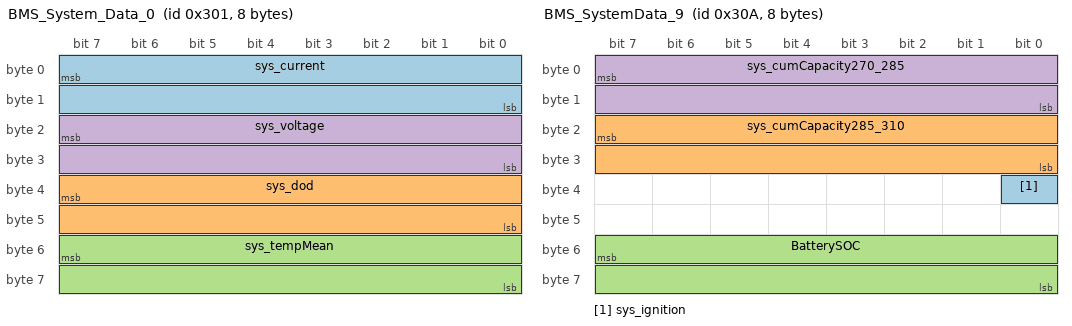
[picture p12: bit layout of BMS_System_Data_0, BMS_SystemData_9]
BO_ 769 BMS_System_Data_0: 8 BMS
 SG_ sys_current : 7|16@0- (0.1,0) [-3276.8|3276.7] "A"  PCU
 SG_ sys_dod : 39|16@0+ (0.1,0) [0|6553.5] "%"  PCU
 SG_ sys_tempMean : 55|16@0- (0.1,0) [-3276.8|3276.7] "deg C"  PCU
 SG_ sys_voltage : 23|16@0+ (0.1,0) [0|6553.5] "V"  PCU

BO_ 778 BMS_SystemData_9: 8 BMS
 SG_ sys_ignition : 32|1@0+ (1,0) [0|1] "" Vector__XXX
 SG_ sys_cumCapacity285_310 : 23|16@0+ (1,0) [0|65535] "Ah" Vector__XXX
 SG_ BatterySOC : 55|16@0+ (0.1,0) [0|6553.5] "%" Vector__XXX
 SG_ sys_cumCapacity270_285 : 7|16@0+ (1,0) [0|65535] "Ah" Vector__XXX

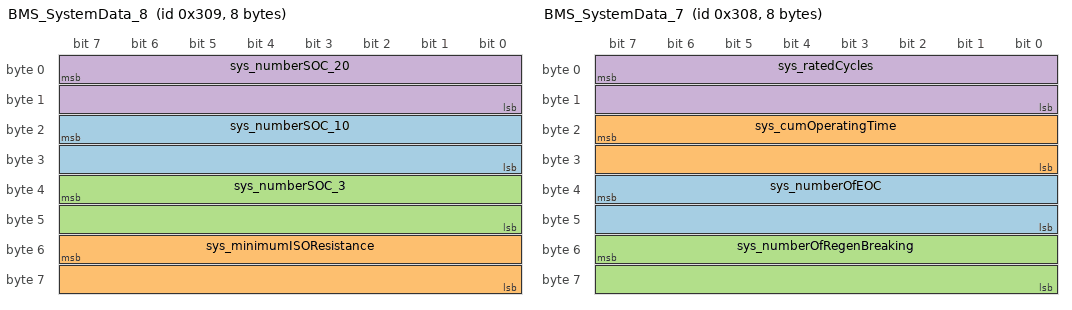
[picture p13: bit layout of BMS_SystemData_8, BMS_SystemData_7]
BO_ 777 BMS_SystemData_8: 8 BMS
 SG_ sys_numberSOC_10 : 23|16@0+ (1,0) [0|65535] "" Vector__XXX
 SG_ sys_minimumISOResistance : 55|16@0+ (1,0) [0|65535] "ohms" Vector__XXX
 SG_ sys_numberSOC_3 : 39|16@0+ (1,0) [0|65535] "" Vector__XXX
 SG_ sys_numberSOC_20 : 7|16@0+ (1,0) [0|65535] "" Vector__XXX

BO_ 776 BMS_SystemData_7: 8 BMS
 SG_ sys_numberOfEOC : 39|16@0+ (1,0) [0|65535] "" Vector__XXX
 SG_ sys_cumOperatingTime : 23|16@0+ (1,0) [0|65535] "days" Vector__XXX
 SG_ sys_numberOfRegenBreaking : 55|16@0+ (1,0) [0|65535] "" Vector__XXX
 SG_ sys_ratedCycles : 7|16@0+ (1,0) [0|65535] "" Vector__XXX

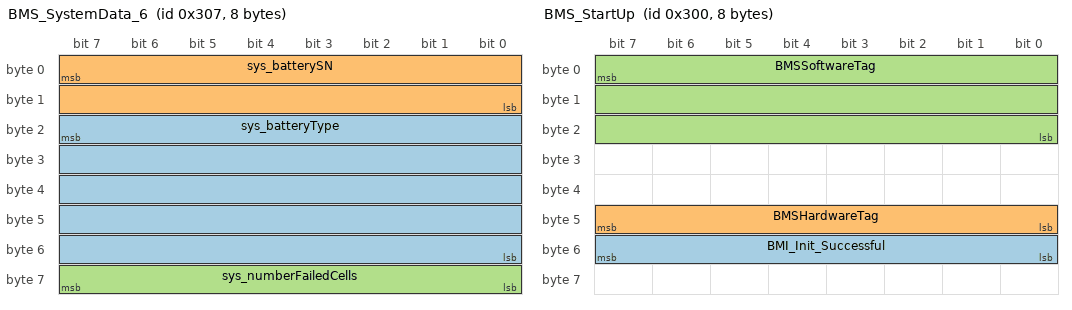
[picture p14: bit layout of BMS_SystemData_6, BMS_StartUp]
BO_ 775 BMS_SystemData_6: 8 BMS
 SG_ sys_batteryType : 23|40@0+ (1,0) [0|1.0995116278E+012] "" Vector__XXX
 SG_ sys_batterySN : 7|16@0+ (1,0) [0|65535] "" Vector__XXX
 SG_ sys_numberFailedCells : 63|8@0+ (1,0) [0|255] "" Vector__XXX

BO_ 768 BMS_StartUp: 8 BMS
 SG_ BMI_Init_Successful : 55|8@0+ (1,0) [0|255] ""  PCU
 SG_ BMSHardwareTag : 47|8@0+ (1,0) [0|1] ""  PCU
 SG_ BMSSoftwareTag : 7|24@0+ (1,0) [0|16777215] ""  PCU

BO_ 783 BMS_SerialNumber2: 8 BMS
 SG_ BatterySerialNumber2 : 7|64@0+ (1,0) [0|1.8446744074E+019] "ASCII"  DiagnosticTester

BO_ 782 BMS_SerialNumber1: 8 BMS
 SG_ BatterySerialNumber1 : 7|64@0+ (1,0) [0|1.8446744074E+019] "ASCII"  DiagnosticTester

BO_ 1827 BMS_Diagnostic_Faults_3: 8 BMS

BO_ 1826 BMS_Diagnostic_Faults_2: 8 BMS

BO_ 1825 BMS_Diagnostic_Faults_1: 8 BMS

BO_ 1869 BMS_Diagnostic: 8 BMS

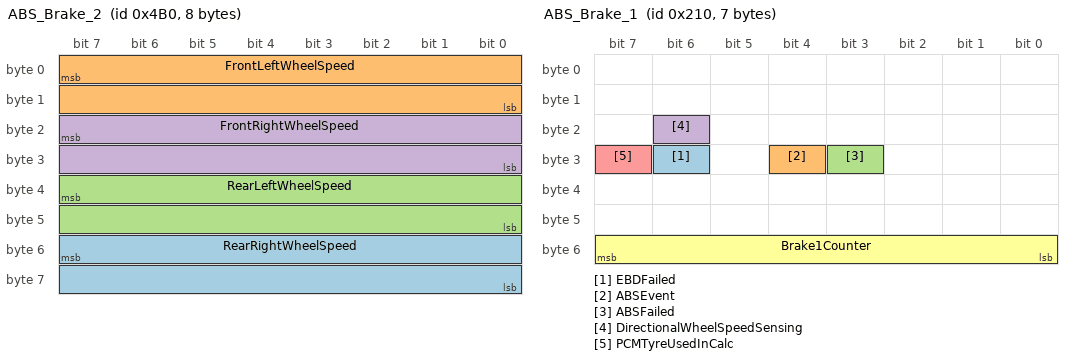
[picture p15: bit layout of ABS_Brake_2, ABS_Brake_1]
BO_ 1200 ABS_Brake_2: 8 ABS
 SG_ RearRightWheelSpeed : 55|16@0+ (0.0091666666667,-91.66667) [-91.66667|275] "km/h" Vector__XXX
 SG_ FrontLeftWheelSpeed : 7|16@0+ (0.0091666666667,-91.66667) [-91.66667|275] "km/h" Vector__XXX
 SG_ RearLeftWheelSpeed : 39|16@0+ (0.0091666666667,-91.66667) [-91.66667|275] "km/h" Vector__XXX
 SG_ FrontRightWheelSpeed : 23|16@0+ (0.0091666666667,-91.66667) [-91.66667|275] "km/h" Vector__XXX

BO_ 528 ABS_Brake_1: 7 ABS
 SG_ EBDFailed : 30|1@0+ (1,0) [0|1] ""  PCU
 SG_ ABSEvent : 28|1@0+ (1,0) [0|1] ""  PCU
 SG_ ABSFailed : 27|1@0+ (1,0) [0|1] ""  PCU
 SG_ DirectionalWheelSpeedSensing : 22|1@0+ (1,0) [0|1] ""  PCU
 SG_ PCMTyreUsedInCalc : 31|1@0+ (1,0) [0|1] ""  PCU
 SG_ Brake1Counter : 55|8@0+ (1,0) [0|255] ""  PCU

CM_ BO_ 1323 "Reserved for Zebra BMI. Do not use if possible";
CM_ BO_ 1322 "Reserved for Zebra BMI. Do not use if possible";
CM_ BO_ 1321 "Reserved for Zebra BMI. Do not use if possible";
CM_ BO_ 1320 "Reserved for Zebra BMI. Do not use if possible";
CM_ BO_ 1319 "Reserved for Zebra BMI. Do not use if possible";
CM_ BO_ 1318 "Reserved for Zebra BMI. Do not use if possible";
CM_ BO_ 1317 "Reserved for Zebra BMI. Do not use if possible";
CM_ BO_ 1316 "Reserved for Zebra BMI. Do not use if possible";
CM_ BO_ 1315 "Reserved for Zebra BMI. Do not use if possible";
CM_ BO_ 779 "Reserved for Zebra BMI. Do not use";
CM_ BO_ 1314 "Reserved for Zebra BMI. Do not use if possible";
CM_ BO_ 1313 "Reserved for Zebra BMI. Do not use if possible";
CM_ BO_ 1312 "Reserved for Zebra BMI. Do not use if possible";
CM_ BO_ 1311 "Reserved for Zebra BMI. Do not use if possible";
CM_ BO_ 1310 "Reserved for Zebra BMI. Do not use if possible";
CM_ BO_ 1309 "Reserved for Zebra BMI. Do not use if possible";
CM_ BO_ 1308 "Reserved for Zebra BMI. Do not use if possible";
CM_ BO_ 1307 "Reserved for Zebra BMI. Do not use if possible";
CM_ BO_ 1306 "Reserved for Zebra BMI. Do not use if possible";
CM_ BO_ 1305 "Reserved for Zebra BMI. Do not use if possible";
CM_ BO_ 1304 "Reserved for Zebra BMI. Do not use if possible";
CM_ BO_ 1303 "Reserved for Zebra BMI. Do not use if possible";
CM_ BO_ 1302 "Reserved for Zebra BMI. Do not use if possible";
CM_ BO_ 1301 "Reserved for Zebra BMI. Do not use if possible";
CM_ BO_ 1300 "Reserved for Zebra BMI. Do not use if possible";
CM_ BO_ 1299 "Reserved for Zebra BMI. Do not use if possible";
CM_ BO_ 1298 "Reserved for Zebra BMI. Do not use if possible";
CM_ BO_ 1297 "Reserved for Zebra BMI. Do not use if possible";
CM_ BO_ 1296 "Reserved for Zebra BMI. Do not use if possible";
CM_ BO_ 1295 "Reserved for Zebra BMI. Do not use if possible";
CM_ BO_ 1294 "Reserved for Zebra BMI. Do not use if possible";
CM_ BO_ 1293 "Reserved for Zebra BMI. Do not use if possible";
CM_ BO_ 1292 "Reserved for Zebra BMI. Do not use if possible";
CM_ BO_ 1291 "Reserved for Zebra BMI. Do not use if possible";
CM_ BO_ 1290 "Reserved for Zebra BMI. Do not use if possible";
CM_ BO_ 1289 "Reserved for Zebra BMI. Do not use if possible";
CM_ BO_ 1288 "Reserved for Zebra BMI. Do not use if possible";
CM_ BO_ 1287 "Reserved for Zebra BMI. Do not use if possible";
CM_ BO_ 1286 "Reserved for Zebra BMI. Do not use if possible";
CM_ BO_ 1285 "Reserved for Zebra BMI. Do not use if possible";
CM_ BO_ 1284 "Reserved for Zebra BMI. Do not use if possible";
CM_ BO_ 1283 "Reserved for Zebra BMI. Do not use if possible";
CM_ BO_ 1282 "Reserved for Zebra BMI. Do not use if possible";
CM_ BO_ 1281 "Reserved for Zebra BMI. Do not use if possible";
CM_ BO_ 1280 "Reserved for Zebra BMI. Do not use if possible";
CM_ BO_ 1909 "PAS may react to this frame. DO NOT TRANSMIT AT ANY MOMENT";
CM_ BO_ 1906 "PAS may react to this frame. DO NOT TRANSMIT AT ANY MOMENT";
CM_ BO_ 146 "PAS may react to this frame. DO NOT TRANSMIT AT ANY MOMENT";
CM_ BO_ 520 "PAS may react to this frame. DO NOT TRANSMIT AT ANY MOMENT";
CM_ BO_ 128 "A different version of ABS might use this frame. Do not use if possible.";
CM_ BO_ 1120 "Period of transmission if node active: 100ms";
CM_ BO_ 35 "Period of transmission if node active: 200ms";
CM_ SG_ 35 RCM_FuelCutOff "0 = Reserved, 
1 = Terminate fuel, 
2 = Normal Op, 
3= unknown.
IMPORTANT! 
Terminate fuel means that all high voltage units shall shut off high voltage operation
";
CM_ SG_ 35 RCM_EventNotification "0 = Inactive
1 = Airbag Deployed";
CM_ BO_ 1664 "Propietary diagnostic frame for RCM";
CM_ BO_ 1855 "Diagnostic Response from RCM ";
CM_ BO_ 1872 "Period of transmission if node active: 5000ms";
CM_ SG_ 1872 RAC_SW_minor "xxx.XXX.xxx in version number";
CM_ SG_ 1872 RAC_HW_minor "xxx.XXX in version number";
CM_ SG_ 1872 RAC_SW_patch "xxx.xxx.XXX in version number";
CM_ SG_ 1872 RAC_SW_major "XXX.xxx.xxx in version number";
CM_ SG_ 1872 RAC_HW_major "XXX.xxx in version number";
CM_ BO_ 1874 "Period of transmission if node active: 1000ms";
CM_ SG_ 1874 VIN_Data "ASCII

If VIN_Index ==3, last byte is to be discarded.";
CM_ BO_ 1027 "Period of transmission if node active: 1000ms";
CM_ SG_ 1027 TimeMonth "0=January";
CM_ BO_ 1025 "Period of transmission if node active: 500ms";
CM_ SG_ 1025 MemoryManagementStatus "This flag indicates if a memory application is running at the moment";
CM_ SG_ 1025 CarState "RAC assumption of CarState. 

Will be Charge if PilotSignalPresent is present.
Will be Drive if Key in Ignition.
Will be Park in other cases.

This signal does not describe the car, it is just assumption and should not be used as vehicle controller signal.";
CM_ SG_ 1025 AirbagLampStatus "When key run is not in ignition, value must be off";
CM_ SG_ 1025 GPSSatellites "Number of satellites GPS is using";
CM_ SG_ 1025 SoundLevel "0: Off or not programmed. 1: Lowest. 5: Highest";
CM_ BO_ 1030 "Period of transmission if node active 5000ms";
CM_ SG_ 1030 RACSerialNumber2 "Least significant part of RAC serial number";
CM_ BO_ 1029 "Period of transmission if node active 5000ms";
CM_ SG_ 1029 RACSerialNumber1 "Most significant part of RAC serial number";
CM_ BO_ 1028 "Period of transmission if node active: 500ms";
CM_ BO_ 1024 "For future development";
CM_ BO_ 1904 "Period of transmission if node active: 5000ms";
CM_ BO_ 1026 "Only present when car sharing activated.
Period of transmission if node active: 500ms";
CM_ BO_ 785 "think_img discharge_wakeup.pdf think_img discharge_shutdown.pdf think_img charge_termcableout.pdf think_img charge_wakeuppilot.pdf
Period of transmission if node active: 200ms";
CM_ SG_ 785 FastChargeRequest "Indicates fast charge request
0 = Fast charge not requested
1 = Fast charge requested
";
CM_ SG_ 785 BatteryChargeRequest "think_img charge_termcableout.pdf think_img charge_termEOC.pdf think_img charge_chginterruptBMS.pdf think_img charge_chginit.pdf 
Indicates that BMI may request charging power from PCU charger
0 = Battery charge not requested,
1 = Battery charge requested 
";
CM_ SG_ 785 AvailableMainsCurrent "Maximum available mains AC current";
CM_ BO_ 514 "Period of transmission if node active: 10ms";
CM_ BO_ 595 "Only under request in certain conditions";
CM_ BO_ 594 "Only under request in certain conditions";
CM_ BO_ 784 "think_img discharge_wakeup.pdf think_img discharge_shutdown.pdf think_img charge_termcableout.pdf think_img charge_wakeuppilot.pdf
Period of transmission if node active: 200ms";
CM_ SG_ 784 TIM_Status "Indicates PCU traction inverter module (TIM) status
0 = TIM disabled
1 = TIM enabled
";
CM_ SG_ 784 Charger_Status "Indicates PCU charger status
0 = PCU charger disabled
1 = PCU charger enabled
";
CM_ SG_ 784 DC_DC_Status "Indicates PCU DC-DC converter status
0 = DC-DC disabled
1 = DC-DC enabled
";
CM_ SG_ 784 PCU_Fault "Indicating high level PCU fault status
0 = No PCU faults affecting PCU high voltage functions
1 = PCU fault detected resulting in disabling of PCU high voltage functions
";
CM_ SG_ 784 BroadcastMode "CAN bus communication mode
0 = Request mode
1= Broadcast mode

Set to 1.
";
CM_ BO_ 849 "Event driven frame. Answer to frame 0x350";
CM_ SG_ 849 ChargerRequest "Same value as LogInRequest received";
CM_ SG_ 849 ChargerAssignedID "Value between 0x01 and 0xFE. 0x00 must be considered not valid.";
CM_ BO_ 613 "Period of transmission if node active: 100ms";
CM_ SG_ 613 SpeedIndication "For driver information display";
CM_ SG_ 613 CustomerDODIndication "for driver information display only";
CM_ SG_ 613 EconometerIndication "For driver information display only";
CM_ BO_ 612 "Period of transmission if node active: 200ms";
CM_ SG_ 612 PASEnable "PCU indicates the PAS system if it is allowed to work and use power or not.";
CM_ SG_ 612 ESPIndication "For driver information display only.";
CM_ SG_ 612 PowerLimitIndication "For driver information display only.";
CM_ SG_ 612 EconomyIndication "For driver information display only.";
CM_ SG_ 612 ABSWarningIndication "For driver information display only.";
CM_ SG_ 612 ElectricHzIndication "For driver information display only.";
CM_ SG_ 612 BrakeWarningIndication "For driver information display only.";
CM_ SG_ 612 OvertempIndication "For driver information display only.";
CM_ SG_ 612 NeutralIndication "For driver information display only.";
CM_ SG_ 612 MILIndication "For driver information display only.";
CM_ SG_ 612 ChargingIndication "For driver information display only.";
CM_ SG_ 612 AuxiliaryBatteryLowIndication "For driver information display only.";
CM_ SG_ 612 DriveEnableIndication "For driver information display only.";
CM_ SG_ 612 OnPlugIndication "For driver information display only.";
CM_ SG_ 612 ParkIndication "For driver information display only.";
CM_ SG_ 612 ReverseIndication "For driver information display only.";
CM_ SG_ 612 LowSOCIndication "For driver information display only.";
CM_ SG_ 612 PilotSignalPresent "PilotSignalPresent indicates wheter the pilot signal from the PCS is present and accepted. It is indirectly indicated that the car is connected to the mains.";
CM_ SG_ 612 DriveIndication "For driver information display only.";
CM_ BO_ 611 "think_img discharge_wakeup.pdf think_img discharge_shutdown.pdf think_img charge_termcableout.pdf think_img charge_wakeuppilot.pdf
Period of transmission if node active: 500ms";
CM_ SG_ 611 SLI_Voltage "Starting-Lighting-Ignition battery voltage";
CM_ SG_ 611 SLI_AmbientTemperature "Starting-Lighting-Ignition battery temperature";
CM_ SG_ 611 VehicleSpeedCounter "SpeedCounter will increase if value of signal VehicleSpeed is correct. Will go from 0xFF to 0x00. Counter will not increase if value is wrong.";
CM_ SG_ 611 VehicleSpeed "Vehicle speed in kilometers per hour";
CM_ BO_ 593 "Period of transmission if node active: 100 ms ";
CM_ BO_ 1883 "Diagnostic Response from PCU";
CM_ BO_ 850 "Period of transmission if node active: 200ms";
CM_ SG_ 850 ChargerOutputPowerDemand "Percemtage of full charge output power. Allows real time PCU control of charger relative output power.";
CM_ SG_ 850 ReceiverID_1 "IDof the receiver. 0xFF is broadcast";
CM_ SG_ 277 PAS_SoftwareVersion "Value downloaded with the calibration file";
CM_ SG_ 277 PAS_VersionMonth "Valid values 1 to 12";
CM_ SG_ 277 PAS_VersionDay "Valid value 1 to 31";
CM_ SG_ 277 PAS_VersionYear "Valid values 00 (2000) to 99 (2099)";
CM_ SG_ 277 PAS_CalibrationIssue "Value downloaded with the calibration file";
CM_ BO_ 1173 "Period of transmission if node active: 100ms

Note: Small delay after transition to ignition on: latests 400ms after transition to ignition on";
CM_ SG_ 1173 PAS_Status "When PAS_Status indicates an error in PAS, a red light must be turn ON in cluster";
CM_ BO_ 1685 "Diagnostic response from PAS";
CM_ BO_ 392 "Period of transmission if node active: 10ms";
CM_ BO_ 391 "Period of transmission if node active: 10ms";
CM_ BO_ 390 "Period of transmission if node active: 10ms";
CM_ BO_ 2000 "Diagnostic Request to VCU";
CM_ BO_ 1921 "Diagnostic request to TPMS";
CM_ BO_ 1665 "Propietary diagnostic frame for RCM";
CM_ BO_ 1847 "Diagnostic Request to RCM";
CM_ BO_ 1875 "Diagnostic Request to PCU";
CM_ BO_ 1717 "Diagnostic request to PAS";
CM_ BO_ 1910 "Diagnostic Request to CDCM";
CM_ BO_ 1861 "Diagnostic request to BMI";
CM_ BO_ 852 "Period of transmission if node active: 200ms";
CM_ SG_ 852 RectifierID_2 "ID of sender";
CM_ SG_ 852 ChargerAvailablePowerPercentage "Percentage of Nominal Power the charger is available to deliver.";
CM_ SG_ 852 ChargerNominalPower "Nominal Power Output from the Charger. PWM command to charger will control a percentage of this value.";
CM_ BO_ 851 "Period of transmission if node active: 200ms";
CM_ SG_ 851 RectifierID_1 "ID of sender";
CM_ SG_ 851 ChargerDCCurrent "Use only positive values";
CM_ SG_ 851 ChargerStatus "Rest of values should be considered as reserved, and not acted upon.";
CM_ BO_ 1640 "Charger download frame";
CM_ BO_ 1639 "Charger download frame";
CM_ BO_ 848 "Period of transmission if node active and not logged in: 1000ms";
CM_ BO_ 853 "Period of transmission if node active: 200ms";
CM_ SG_ 853 CommunicationFailure "Communication error between primary and secondary.";
CM_ SG_ 853 CurrentLimitError "Warning: current limited due to some error";
CM_ SG_ 853 ControllerCommunicationError "CAN communication with the PCU missing";
CM_ SG_ 853 ModuleFailureError "Boost running, but DCDC failure";
CM_ SG_ 853 RectifierID_3 "ID of sender";
CM_ BO_ 1032 "Period of transmission if node active: 500ms";
CM_ SG_ 1032 CDCMFrontDemistSwitch "This signal shows the state of the input to the CDCM";
CM_ SG_ 1032 CDCMRearDemistSwitch "This signal shows the state of the input to the CDCM";
CM_ SG_ 1032 CDCMHWVersion "HW version";
CM_ SG_ 1032 ACPresent "Signal indicates if CDCM has AC capabilities";
CM_ SG_ 1032 CDCMKeyRun "This signal shows the state of the input to the CDCM";
CM_ SG_ 1032 CDCMWakeUp "This signal shows the state of the input to the CDCM";
CM_ SG_ 1032 CDCMSWVersion "SW version";
CM_ SG_ 1032 CDCM12VSupply "Signal indicates the measured 12V votage by the CDCM";
CM_ SG_ 1032 CDCMHeaterFault "This signal shows the state of the input to the CDCM";
CM_ SG_ 1032 CDCMHVRequest "This signal shows the state of the output from the CDCM";
CM_ SG_ 1032 CDCMFrontDemist1 "This signal shows the state of the output from the CDCM";
CM_ SG_ 1032 CDCMCondenserFan "This signal shows the state of the output from the CDCM";
CM_ SG_ 1032 EvaporatorTemperature "Indicates the evaporator temperature.";
CM_ SG_ 1032 CDCMHeaterEnable "This signal shows the state of the output from the CDCM";
CM_ SG_ 1032 CDCMInverterSupply "This signal shows the state of the output from the CDCM";
CM_ SG_ 1032 CDCMForcedBlower "This signal shows the state of the output from the CDCM";
CM_ SG_ 1032 CDCMFrontDemist2 "This signal shows the state of the output from the CDCM";
CM_ SG_ 1032 HeaterKnobPosition "Signal indicates the heater knob position.";
CM_ SG_ 1032 CDCMRearDemist "This signal shows the state of the output from the CDCM";
CM_ SG_ 1032 CDCMOperationState "State of operation of the CDCM
";
CM_ SG_ 1032 CDCMACRequest "This signal shows the state of the input to the CDCM";
CM_ BO_ 69 "Period of transmission if node active: 200ms";
CM_ BO_ 1033 "Period of transmission if node active: 500ms";
CM_ SG_ 1033 KnobPositionTooHigh "CDCM Error Flag";
CM_ SG_ 1033 CondenserFanOC "CDCM Error Flag";
CM_ SG_ 1033 PTCCommunicationBroken "PTC will not work";
CM_ SG_ 1033 RearDemistSC "CDCM Error Flag";
CM_ SG_ 1033 PTCHVMissing "BMS will open contactors. Service needed.";
CM_ SG_ 1033 HVrequestSC "CDCM Error Flag";
CM_ SG_ 1033 FrontDemist2OC "CDCM Error Flag";
CM_ SG_ 1033 FluidHeaterFaultLineOld "Do not use for DTCs";
CM_ SG_ 1033 ClimateCANTimeout "CDCM Error Flag";
CM_ SG_ 1033 KnobPositionTooLow "CDCM Error Flag";
CM_ SG_ 1033 PTCOtherError "Continuous error in the PTC";
CM_ SG_ 1033 HeaterEnableOC "CDCM Error Flag";
CM_ SG_ 1033 HeaterEnableSC "CDCM Error Flag";
CM_ SG_ 1033 CondenserFanSC "CDCM Error Flag";
CM_ SG_ 1033 ForcedBlowerOC "CDCM Error Flag";
CM_ SG_ 1033 InverterSupplyOC "CDCM Error Flag";
CM_ SG_ 1033 FrontDemist1SC "CDCM Error Flag";
CM_ SG_ 1033 BMSSWNotReady "BMS SW not ready for PTC. PTC will not work. Update SW in BMS.";
CM_ SG_ 1033 ForcedBlowerSC "CDCM Error Flag";
CM_ SG_ 1033 RearDemistOC "CDCM Error Flag";
CM_ SG_ 1033 TemperatureSensorSignalTooLow "CDCM Error Flag";
CM_ SG_ 1033 TemperatureSensorSignalTooHigh "CDCM Error Flag";
CM_ SG_ 1033 InverterSupplySC "CDCM Error Flag";
CM_ SG_ 1033 FrontDemist2SC "CDCM Error Flag";
CM_ SG_ 1033 FrontDemist1OC "CDCM Error Flag";
CM_ SG_ 1033 FluidHeaterFaultLineCurrent "Do not use for DTCs";
CM_ SG_ 1033 PCUSWNotReady "PCU Sw not ready for PTC. PTC will not work. Update SW in PCU.";
CM_ SG_ 1033 VCUSWNotReady "VCU Sw not ready for PTC. PTC will not work. Update SW in VCU.";
CM_ SG_ 1033 HVRequestOC "CDCM Error Flag";
CM_ BO_ 1918 "Diagnostic Response from CDCM";
CM_ BO_ 1035 "Period of transmission if node active: 500ms";
CM_ BO_ 51 "CCP frame for VCU";
CM_ BO_ 1957 "CCP frame for VCU";
CM_ BO_ 1956 "CCP frame for VCU";
CM_ BO_ 1955 "CCP frame for VCU";
CM_ BO_ 50 "CCP frame for VCU";
CM_ BO_ 55 "CCP frame for PCU";
CM_ BO_ 1963 "CCP frame for PCU";
CM_ BO_ 1962 "CCP frame for PCU";
CM_ BO_ 1961 "CCP frame for PCU";
CM_ BO_ 54 "CCP frame for PCU";
CM_ BO_ 53 "CCP frame for Charger";
CM_ BO_ 1960 "CCP frame for Charger";
CM_ BO_ 1959 "CCP frame for Charger";
CM_ BO_ 1958 "CCP frame for Charger";
CM_ BO_ 52 "CCP frame for Charger";
CM_ BO_ 49 "CCP frame for CDCM";
CM_ BO_ 1954 "CCP frame for CDCM";
CM_ BO_ 1953 "CCP frame for CDCM";
CM_ BO_ 1952 "CCP frame for CDCM";
CM_ BO_ 48 "CCP frame for CDCM";
CM_ BO_ 57 "CCP frame for BMS";
CM_ BO_ 1966 "CCP frame for BMS";
CM_ BO_ 1965 "CCP frame for BMS";
CM_ BO_ 1964 "CCP frame for BMS";
CM_ BO_ 56 "CCP frame for BMS";
CM_ BO_ 774 "Period of transmission if node active: 1s
";
CM_ SG_ 774 BatteryLinearAge "Value 0 shall be indicated when the battery was manufactured. Value 20000 shall indicate that the battery has just reached its estimated expected lifetime. Signal should increment pass 20000 in a normal way once achieved.";
CM_ SG_ 774 RelativeEnergyContent "RelativeEnergyContent is a signal used by the battery to indicate the aproximate value of Capacity respect original nominal capacity.
Batteries will be considered 'used' when this signal reaches an 80% value.";
CM_ SG_ 774 EquivalentInternalResistance "Measurement of the battery equivalent internal resistance";
CM_ BO_ 773 "think_img discharge_wakeup.pdf think_img discharge_shutdown.pdf think_img charge_termcableout.pdf think_img charge_wakeuppilot.pdf
Period of transmission if node active: 200ms";
CM_ SG_ 773 sys_intIsoError "Indicates high voltage DC isolation fault has been detected whose source is internal to the traction battery 
0 = Internal isolation fault not detected 
1 = Internal isolation fault detected
";
CM_ SG_ 773 sys_BMI_state "Signal used by the BMS to indicate the state he is currently functioning";
CM_ SG_ 773 Battery_Type "Traction battery type identification
0 = Z36 
1 = Z5
2 = EnerDel Li-Ion
3 = A123 Li-Ion
4-7 = TBD
";
CM_ SG_ 773 BatteryChargeEN "think_img charge_termcableout.pdf think_img charge_termEOC.pdf think_img charge_chginterruptBMS.pdf think_img charge_chginit.pdf 
Indicating status of the traction battery main contactors for charging.
0 = Traction battery contactors open
1 = Traction battery contactors closed for charge.
";
CM_ SG_ 773 Charger_PWM_Cmd "Percentage of full charger output power.
Allows real-time BMI control of charger relative output power level
";
CM_ SG_ 773 Waiting_OK_Temp_Discharge "Indication that traction battery pre-heating or pre-cooling is in progress and that discharging will be delayed until traction battery temperature is within limits for discharging.
0 = Discharge not delayed
1 = Discharge delayed until temperature within limits 
";
CM_ SG_ 773 sys_extIsoError "Indicates high voltage DC isolation fault has been detected whose source is external to the traction battery
0 = External isolation fault not detected
1 = External isolation fault detected
";
CM_ SG_ 773 sys_BMITempError "Indicates temperature error has been detected within BMI
0 = OK 
1 = BMI temperature > 65 degrees Celsius 
2 = BMI temperature > 75 degrees Celsius
3 = BMI overtemp shutdown
";
CM_ SG_ 773 No_Charge_Current "Indication from BMI that there is no charge current into the traction battery for 5 minutes, after non-zero charger PWM command
0 = No charge current fault detected 
1 = Charge current fault detected
";
CM_ SG_ 773 Charge_Interrupt "think_img charge_chginterruptBMS.pdf ";
CM_ SG_ 773 sys_thermalIsoError "Indicates thermal isolation fault has been detected.
0 = Thermal isolation fault not detected
1 = Thermal isolation fault detected

Active if:
-Thermal Iso set
-DC heater on for 1 hour and Temp does not increase
-AC heater on for 22 hours and Temp does not reach 200 deg C
-AC heater on and temp increases by more that 30 deg per hour
-AC heater on and the temperature is less than 0 deg C

";
CM_ SG_ 773 SOCAdaptationOutOfRange "Applicable if the BSOC calculation can deviate too much from the real SOC and is no longer possible to adpat to the real SOC without consulting service personel. For Zebra, the 'EOC with SOC < 80%' fault has been triggered.";
CM_ SG_ 773 sys_ZebraTempError "Indicates temperature error has been detected within Zebra
0 = OK 
1 = Power Limit Temp reached 
2 = Full Power Limit Temp reached
3 = Full Power Limit Temp reached
";
CM_ BO_ 772 "think_img discharge_wakeup.pdf think_img discharge_shutdown.pdf think_img charge_termcableout.pdf think_img charge_wakeuppilot.pdf
Period of transmission if node active: 200ms";
CM_ SG_ 772 AC_Heater_Relay_Status "Status of the AC heater relay. Only for Zebra
0 = AC heater relay open,
1 = AC heater relay closed
Active (=1) 6 seconds before and after AC heater relay closed
";
CM_ SG_ 772 Too_Many_Failed_Cells "Indicates that 10 percent or more of the cells/strings in Zebra traction battery have failed. Only for Zebra

0 = <10% failed cells/strings or new
1 = >=10% failed cells/strings or too aged
";
CM_ SG_ 772 sys_EOC "think_img charge_termEOC.pdf think_img charge_chginit.pdf
Indication that end of charge (EOC) is reached.
0 = EOC not reached, SOC <98%
1 = EOC reached. SOC = 100%, reset to 0 at SOC<98%
";
CM_ SG_ 772 Waiting_OK_Temp_Charge "Indication that traction battery pre-heating or pre-cooling is in progress and that charging will be delayed until traction battery temperature is within limits for charging.
0 = Charge not delayed
1 = Charge delayed until temperatur within limits.
This bit is only valid during charging.
";
CM_ SG_ 772 sys_highestErrCat "Highest error category among active errors in traction battery system detected by BMI:
0 = No error
1 = Category statistic fault detected (least serious)
2 = Category notice fault detected
3 = Category delayed switch off fault detected
4 = Category switch off fault detected (most serious)
5-F = TBD
";
CM_ SG_ 772 Reach_EOC_please "BMI indication that a complete charge should be performed soon to avoid poor SOC accuracy.
0 = Battery does not need to reach EOC
1 = Battery needs to reach EOC 
General rule of thumb: a vehicle driven everyday needs to reach end of charge (EOC) at least once each week.
";
CM_ SG_ 772 AC_Heater_Switch_Status "Real-time status of PWM-controlled traction battery AC heater switch. Only for batteries with AC heater. Set to 0 if no AC heater present.
0 = AC heater switch open,
1 = AC heater switch closed
";
CM_ BO_ 771 "think_img discharge_wakeup.pdf think_img discharge_shutdown.pdf think_img charge_termcableout.pdf think_img charge_wakeuppilot.pdf
Period of transmission if node active: 200ms";
CM_ SG_ 771 sys_dischargeEN "think_img discharge_wakeup.pdf think_img discharge_shutdown.pdf 
Acknowledge signal from the traction battery stating that contactors are closed and that the traction battery is ready for high voltage loads 
0 = Discharge disabled.
1 = Discharge enabled
Maximum 1 second delay allowed between change of Sys_DischargeEN signal and actual open/closed status of main contactors.
";
CM_ SG_ 771 sys_currentMaxCharge "Real-time maximum traction battery charge/regen current limit (abs. value)";
CM_ SG_ 771 sys_emergency "Indicates that a vehicle emergency situation has been detected
0 = No vehicle emergency detected
1 = Emergency power off (EPO) input active OR 
RCM_FuelCutoff set to 'Terminate Fuel' in message ID 0x23
";
CM_ SG_ 771 sys_fastchargeEN "Allows a fast charge function
0 = Fast charge disabled
1 = Fast charge enabled.
";
CM_ SG_ 771 sys_regenBrakingEN "Real-time indication that traction battery is capable of accepting regenerative braking current 
0 = Regen braking disabled
1 = Regen braking enabled.
";
CM_ SG_ 771 sys_crash "Indicates that a vechicle crash situation has been detected.
0 = No crash detected 
1 = BMI CrashInput1 active (only for Zebra) OR 
RCM_EventNotification bit set in msg ID 0x23
";
CM_ SG_ 771 sys_fan_status "Indicates on/off status of the traction battery fan, controlled by the BMI
0 = Fan not active
1 = Fan active
";
CM_ SG_ 771 sys_SOCGreater102 "Indicates that the traction battery State of charge (SOC) is greater than 102%
0 = State of charge < 102%
1 = State of charge < 102%
";
CM_ SG_ 771 sys_waiting_temp_err "Indication that traction battery pre-heating or pre-cooling is in progress and that charging/discharging will be delayed until traction battery temperature is within limits for charging/discharging.
0 = No charge delay
1 = Charge delayed until traction battery temperature within limits
";
CM_ SG_ 771 sys_voltageMaxCharge "Real-time maximum traction battery charge/regen voltage limit";
CM_ BO_ 770 "think_img discharge_wakeup.pdf think_img discharge_shutdown.pdf think_img charge_termcableout.pdf think_img charge_wakeuppilot.pdf
Period of transmission if node active: 200ms";
CM_ SG_ 770 sys_currentMaxDischarge "Real-time maximum traction battery discharge current limit (Abs. value)";
CM_ SG_ 770 sys_isoerror "Indicates a high voltage DC isolation fault , internal or external to the traction battery.
0 = Isolation fault not detected
1 = Isolation fault detected
";
CM_ SG_ 770 sys_voltageMinDischarge "Real-time minimum traction battery discharge voltage limit";
CM_ SG_ 770 sys_errGeneral "Indicates that a general fault has been detected.
0 = No faults of this kind detected
1 = Fault of this type detected
Set to 1 if ErrCat ? CATEGORY_NOTICE
";
CM_ BO_ 769 "think_img discharge_wakeup.pdf think_img discharge_shutdown.pdf think_img charge_termcableout.pdf think_img charge_wakeuppilot.pdf
Period of transmission if node active: 200ms";
CM_ SG_ 769 sys_current "Measured, real-time filtered, traction battery current .
Positive = discharge 
Negative = charge.
";
CM_ SG_ 769 sys_dod "Traction Battery Depth of Discharge (DOD). Real-time master signal from the traction battery. Traction Battery State of charge (SOC) = 100 - DOD";
CM_ SG_ 769 sys_tempMean "Measured mean traction battery temperature";
CM_ SG_ 769 sys_voltage "Measured, real-time filtered, traction battery voltage ";
CM_ BO_ 778 "Period of transmission if node active: 30000
Transmitted only if Zebra";
CM_ BO_ 777 "Period of transmission if node active: 30000
Transmitted only if Zebra";
CM_ BO_ 776 "Period of transmission if node active: 30000
Transmitted only if Zebra";
CM_ BO_ 775 "Period of transmission if node active: 30000
Transmitted only if Zebra";
CM_ SG_ 775 sys_batteryType "Battery type read from LDM";
CM_ SG_ 775 sys_batterySN "Battery SN read from LDM";
CM_ BO_ 768 "think_img discharge_wakeup.pdf think_img discharge_shutdown.pdf think_img charge_termcableout.pdf think_img charge_wakeuppilot.pdf
Period of transmission if node active: 200ms";
CM_ SG_ 768 BMI_Init_Successful "BMI power-up initialization self test
0= Initialization failed/Error, 
1= Initialization OK and BMI ready for communication.

Note that only 0x00 and 0x01 are valid values. all the rest are invalid";
CM_ SG_ 768 BMSHardwareTag "BMI hardware version identifier.";
CM_ SG_ 768 BMSSoftwareTag "Released BMI software version identifier.";
CM_ BO_ 783 "Period of transmission if node active: 30s";
CM_ SG_ 783 BatterySerialNumber2 "Least significant part of the battery serial number. Note, it is tied to the battery (chemistry), not BMS";
CM_ BO_ 782 "Period of transmission if node active: 30s";
CM_ SG_ 782 BatterySerialNumber1 "Most significant part of the battery serial number. Note, it is tied to the battery (chemistry), not BMS";
CM_ BO_ 1869 "Diagnostic Response from BMI";
CM_ BO_ 1200 "Period of transmission if node active: 14ms";
CM_ BO_ 528 "Period of transmission if node active: 14ms";
CM_ SG_ 528 Brake1Counter "Increasing counter every frame";
BA_DEF_ BO_  "GenMsgCycleTimeFast" INT 0 0;
BA_DEF_ BO_  "GenMsgCycleTime" INT 0 0;
BA_DEF_ BO_  "GenMsgSendType" ENUM  "Cyclic","NotUsed","NotUsed","NotUsed","NotUsed","NotUsed","NotUsed","IfActive","NoMsgSendType","NotUsed";
BA_DEF_ SG_  "GenSigStartValue" FLOAT 0 0;
BA_DEF_ SG_  "GenSigCycleTimeActive" INT 0 0;
BA_DEF_ SG_  "GenSigCycleTime" INT 0 0;
BA_DEF_ SG_  "GenSigSendType" ENUM  "Cyclic","OnWrite","OnWriteWithRepetition","OnChange","OnChangeWithRepetition","IfActive","IfActiveWithRepetition","NoSigSendType","NotUsed","NotUsed","NotUsed","NotUsed","NotUsed";
BA_DEF_DEF_  "GenMsgCycleTimeFast" 0;
BA_DEF_DEF_  "GenMsgCycleTime" 0;
BA_DEF_DEF_  "GenMsgSendType" "Cyclic";
BA_DEF_DEF_  "GenSigStartValue" 0;
BA_DEF_DEF_  "GenSigCycleTimeActive" 0;
BA_DEF_DEF_  "GenSigCycleTime" 0;
BA_DEF_DEF_  "GenSigSendType" "Cyclic";
BA_ "GenMsgCycleTime" BO_ 1323 100;
BA_ "GenMsgCycleTimeFast" BO_ 1323 100;
BA_ "GenMsgCycleTime" BO_ 1322 100;
BA_ "GenMsgCycleTimeFast" BO_ 1322 100;
BA_ "GenMsgCycleTime" BO_ 1321 100;
BA_ "GenMsgCycleTimeFast" BO_ 1321 100;
BA_ "GenMsgCycleTime" BO_ 1320 100;
BA_ "GenMsgCycleTimeFast" BO_ 1320 100;
BA_ "GenMsgCycleTime" BO_ 1319 100;
BA_ "GenMsgCycleTimeFast" BO_ 1319 100;
BA_ "GenMsgCycleTime" BO_ 1318 100;
BA_ "GenMsgCycleTimeFast" BO_ 1318 100;
BA_ "GenMsgCycleTime" BO_ 1317 100;
BA_ "GenMsgCycleTimeFast" BO_ 1317 100;
BA_ "GenMsgCycleTime" BO_ 1316 100;
BA_ "GenMsgCycleTimeFast" BO_ 1316 100;
BA_ "GenMsgCycleTime" BO_ 1315 100;
BA_ "GenMsgCycleTimeFast" BO_ 1315 100;
BA_ "GenMsgCycleTime" BO_ 779 100;
BA_ "GenMsgCycleTimeFast" BO_ 779 100;
BA_ "GenMsgCycleTime" BO_ 1314 100;
BA_ "GenMsgCycleTimeFast" BO_ 1314 100;
BA_ "GenMsgCycleTime" BO_ 1313 100;
BA_ "GenMsgCycleTimeFast" BO_ 1313 100;
BA_ "GenMsgCycleTime" BO_ 1312 100;
BA_ "GenMsgCycleTimeFast" BO_ 1312 100;
BA_ "GenMsgCycleTime" BO_ 1311 100;
BA_ "GenMsgCycleTimeFast" BO_ 1311 100;
BA_ "GenMsgCycleTime" BO_ 1310 100;
BA_ "GenMsgCycleTimeFast" BO_ 1310 100;
BA_ "GenMsgCycleTime" BO_ 1309 100;
BA_ "GenMsgCycleTimeFast" BO_ 1309 100;
BA_ "GenMsgCycleTime" BO_ 1308 100;
BA_ "GenMsgCycleTimeFast" BO_ 1308 100;
BA_ "GenMsgCycleTime" BO_ 1307 100;
BA_ "GenMsgCycleTimeFast" BO_ 1307 100;
BA_ "GenMsgCycleTime" BO_ 1306 100;
BA_ "GenMsgCycleTimeFast" BO_ 1306 100;
BA_ "GenMsgCycleTime" BO_ 1305 100;
BA_ "GenMsgCycleTimeFast" BO_ 1305 100;
BA_ "GenMsgCycleTime" BO_ 1304 100;
BA_ "GenMsgCycleTimeFast" BO_ 1304 100;
BA_ "GenMsgCycleTime" BO_ 1303 100;
BA_ "GenMsgCycleTimeFast" BO_ 1303 100;
BA_ "GenMsgCycleTime" BO_ 1302 100;
BA_ "GenMsgCycleTimeFast" BO_ 1302 100;
BA_ "GenMsgCycleTime" BO_ 1301 100;
BA_ "GenMsgCycleTimeFast" BO_ 1301 100;
BA_ "GenMsgCycleTime" BO_ 1300 100;
BA_ "GenMsgCycleTimeFast" BO_ 1300 100;
BA_ "GenMsgCycleTime" BO_ 1299 100;
BA_ "GenMsgCycleTimeFast" BO_ 1299 100;
BA_ "GenMsgCycleTime" BO_ 1298 100;
BA_ "GenMsgCycleTimeFast" BO_ 1298 100;
BA_ "GenMsgCycleTime" BO_ 1297 100;
BA_ "GenMsgCycleTimeFast" BO_ 1297 100;
BA_ "GenMsgCycleTime" BO_ 1296 100;
BA_ "GenMsgCycleTimeFast" BO_ 1296 100;
BA_ "GenMsgCycleTime" BO_ 1295 100;
BA_ "GenMsgCycleTimeFast" BO_ 1295 100;
BA_ "GenMsgCycleTime" BO_ 1294 100;
BA_ "GenMsgCycleTimeFast" BO_ 1294 100;
BA_ "GenMsgCycleTime" BO_ 1293 100;
BA_ "GenMsgCycleTimeFast" BO_ 1293 100;
BA_ "GenMsgCycleTime" BO_ 1292 100;
BA_ "GenMsgCycleTimeFast" BO_ 1292 100;
BA_ "GenMsgCycleTime" BO_ 1291 100;
BA_ "GenMsgCycleTimeFast" BO_ 1291 100;
BA_ "GenMsgCycleTime" BO_ 1290 100;
BA_ "GenMsgCycleTimeFast" BO_ 1290 100;
BA_ "GenMsgCycleTime" BO_ 1289 100;
BA_ "GenMsgCycleTimeFast" BO_ 1289 100;
BA_ "GenMsgCycleTime" BO_ 1288 100;
BA_ "GenMsgCycleTimeFast" BO_ 1288 100;
BA_ "GenMsgCycleTime" BO_ 1287 100;
BA_ "GenMsgCycleTimeFast" BO_ 1287 100;
BA_ "GenMsgCycleTime" BO_ 1286 100;
BA_ "GenMsgCycleTimeFast" BO_ 1286 100;
BA_ "GenMsgCycleTime" BO_ 1285 100;
BA_ "GenMsgCycleTimeFast" BO_ 1285 100;
BA_ "GenMsgCycleTime" BO_ 1284 100;
BA_ "GenMsgCycleTimeFast" BO_ 1284 100;
BA_ "GenMsgCycleTime" BO_ 1283 100;
BA_ "GenMsgCycleTimeFast" BO_ 1283 100;
BA_ "GenMsgCycleTime" BO_ 1282 100;
BA_ "GenMsgCycleTimeFast" BO_ 1282 100;
BA_ "GenMsgCycleTime" BO_ 1281 100;
BA_ "GenMsgCycleTimeFast" BO_ 1281 100;
BA_ "GenMsgCycleTime" BO_ 1280 100;
BA_ "GenMsgCycleTimeFast" BO_ 1280 100;
BA_ "GenMsgCycleTime" BO_ 1909 100;
BA_ "GenMsgCycleTimeFast" BO_ 1909 100;
BA_ "GenMsgCycleTime" BO_ 1906 100;
BA_ "GenMsgCycleTimeFast" BO_ 1906 100;
BA_ "GenMsgCycleTime" BO_ 146 100;
BA_ "GenMsgCycleTimeFast" BO_ 146 100;
BA_ "GenMsgCycleTime" BO_ 520 100;
BA_ "GenMsgCycleTimeFast" BO_ 520 100;
BA_ "GenMsgCycleTime" BO_ 128 100;
BA_ "GenMsgCycleTimeFast" BO_ 128 100;
BA_ "GenMsgCycleTime" BO_ 1120 100;
BA_ "GenMsgCycleTimeFast" BO_ 1120 100;
BA_ "GenMsgCycleTime" BO_ 35 200;
BA_ "GenMsgCycleTimeFast" BO_ 35 100;
BA_ "GenMsgCycleTime" BO_ 1664 100;
BA_ "GenMsgCycleTimeFast" BO_ 1664 100;
BA_ "GenMsgCycleTime" BO_ 1855 100;
BA_ "GenMsgCycleTimeFast" BO_ 1855 100;
BA_ "GenMsgCycleTime" BO_ 1872 5000;
BA_ "GenMsgCycleTimeFast" BO_ 1872 100;
BA_ "GenMsgCycleTime" BO_ 1874 10000;
BA_ "GenMsgCycleTimeFast" BO_ 1874 100;
BA_ "GenMsgCycleTime" BO_ 1027 1000;
BA_ "GenMsgCycleTimeFast" BO_ 1027 100;
BA_ "GenMsgCycleTime" BO_ 1025 500;
BA_ "GenMsgCycleTimeFast" BO_ 1025 100;
BA_ "GenMsgCycleTime" BO_ 1030 5000;
BA_ "GenMsgCycleTimeFast" BO_ 1030 100;
BA_ "GenMsgCycleTime" BO_ 1029 5000;
BA_ "GenMsgCycleTimeFast" BO_ 1029 100;
BA_ "GenMsgCycleTime" BO_ 1920 100;
BA_ "GenMsgCycleTimeFast" BO_ 1920 100;
BA_ "GenMsgCycleTime" BO_ 1028 1000;
BA_ "GenMsgCycleTimeFast" BO_ 1028 100;
BA_ "GenMsgCycleTime" BO_ 1024 200;
BA_ "GenMsgCycleTimeFast" BO_ 1024 100;
BA_ "GenMsgCycleTime" BO_ 1897 200;
BA_ "GenMsgCycleTimeFast" BO_ 1897 100;
BA_ "GenMsgCycleTime" BO_ 1904 5000;
BA_ "GenMsgCycleTimeFast" BO_ 1904 100;
BA_ "GenMsgCycleTime" BO_ 1026 500;
BA_ "GenMsgCycleTimeFast" BO_ 1026 100;
BA_ "GenMsgCycleTime" BO_ 785 200;
BA_ "GenMsgCycleTimeFast" BO_ 785 100;
BA_ "GenMsgCycleTime" BO_ 514 10;
BA_ "GenMsgCycleTimeFast" BO_ 514 100;
BA_ "GenMsgSendType" BO_ 595 7;
BA_ "GenMsgCycleTime" BO_ 595 100;
BA_ "GenMsgCycleTimeFast" BO_ 595 100;
BA_ "GenMsgSendType" BO_ 594 7;
BA_ "GenMsgCycleTime" BO_ 594 100;
BA_ "GenMsgCycleTimeFast" BO_ 594 100;
BA_ "GenMsgCycleTime" BO_ 784 200;
BA_ "GenMsgCycleTimeFast" BO_ 784 100;
BA_ "GenMsgCycleTime" BO_ 849 100;
BA_ "GenMsgCycleTimeFast" BO_ 849 100;
BA_ "GenMsgCycleTime" BO_ 613 100;
BA_ "GenMsgCycleTimeFast" BO_ 613 100;
BA_ "GenMsgCycleTime" BO_ 612 500;
BA_ "GenMsgCycleTimeFast" BO_ 612 100;
BA_ "GenMsgCycleTime" BO_ 611 500;
BA_ "GenMsgCycleTimeFast" BO_ 611 100;
BA_ "GenMsgCycleTime" BO_ 593 100;
BA_ "GenMsgCycleTimeFast" BO_ 593 100;
BA_ "GenMsgCycleTime" BO_ 1883 200;
BA_ "GenMsgCycleTimeFast" BO_ 1883 100;
BA_ "GenMsgCycleTime" BO_ 850 200;
BA_ "GenMsgCycleTimeFast" BO_ 850 100;
BA_ "GenMsgCycleTime" BO_ 277 100;
BA_ "GenMsgCycleTimeFast" BO_ 277 100;
BA_ "GenMsgCycleTime" BO_ 1173 100;
BA_ "GenMsgCycleTimeFast" BO_ 1173 100;
BA_ "GenMsgCycleTime" BO_ 1685 100;
BA_ "GenMsgCycleTimeFast" BO_ 1685 100;
BA_ "GenMsgCycleTime" BO_ 392 10;
BA_ "GenMsgCycleTimeFast" BO_ 392 100;
BA_ "GenMsgCycleTime" BO_ 391 10;
BA_ "GenMsgCycleTimeFast" BO_ 391 100;
BA_ "GenMsgCycleTime" BO_ 390 10;
BA_ "GenMsgCycleTimeFast" BO_ 390 100;
BA_ "GenMsgCycleTime" BO_ 2000 100;
BA_ "GenMsgCycleTimeFast" BO_ 2000 100;
BA_ "GenMsgCycleTime" BO_ 1921 100;
BA_ "GenMsgCycleTimeFast" BO_ 1921 100;
BA_ "GenMsgCycleTime" BO_ 1665 100;
BA_ "GenMsgCycleTimeFast" BO_ 1665 100;
BA_ "GenMsgCycleTime" BO_ 1847 100;
BA_ "GenMsgCycleTimeFast" BO_ 1847 100;
BA_ "GenMsgCycleTime" BO_ 1873 100;
BA_ "GenMsgCycleTimeFast" BO_ 1873 100;
BA_ "GenMsgCycleTime" BO_ 1905 100;
BA_ "GenMsgCycleTimeFast" BO_ 1905 100;
BA_ "GenMsgCycleTime" BO_ 1875 100;
BA_ "GenMsgCycleTimeFast" BO_ 1875 100;
BA_ "GenMsgCycleTime" BO_ 1717 100;
BA_ "GenMsgCycleTimeFast" BO_ 1717 100;
BA_ "GenMsgCycleTime" BO_ 1910 100;
BA_ "GenMsgCycleTimeFast" BO_ 1910 100;
BA_ "GenMsgCycleTime" BO_ 1861 100;
BA_ "GenMsgCycleTimeFast" BO_ 1861 100;
BA_ "GenMsgCycleTime" BO_ 852 200;
BA_ "GenMsgCycleTimeFast" BO_ 852 100;
BA_ "GenMsgCycleTime" BO_ 851 200;
BA_ "GenMsgCycleTimeFast" BO_ 851 100;
BA_ "GenMsgCycleTime" BO_ 848 1000;
BA_ "GenMsgCycleTimeFast" BO_ 848 100;
BA_ "GenMsgCycleTime" BO_ 853 200;
BA_ "GenMsgCycleTimeFast" BO_ 853 100;
BA_ "GenMsgCycleTime" BO_ 1032 500;
BA_ "GenMsgCycleTimeFast" BO_ 1032 100;
BA_ "GenMsgCycleTime" BO_ 69 200;
BA_ "GenMsgCycleTimeFast" BO_ 69 100;
BA_ "GenMsgCycleTime" BO_ 1033 500;
BA_ "GenMsgCycleTimeFast" BO_ 1033 100;
BA_ "GenMsgCycleTime" BO_ 1918 100;
BA_ "GenMsgCycleTimeFast" BO_ 1918 100;
BA_ "GenMsgCycleTime" BO_ 1035 100;
BA_ "GenMsgCycleTimeFast" BO_ 1035 100;
BA_ "GenMsgCycleTime" BO_ 774 1000;
BA_ "GenMsgCycleTimeFast" BO_ 774 100;
BA_ "GenMsgCycleTime" BO_ 773 200;
BA_ "GenMsgCycleTimeFast" BO_ 773 100;
BA_ "GenMsgCycleTime" BO_ 772 200;
BA_ "GenMsgCycleTimeFast" BO_ 772 100;
BA_ "GenMsgCycleTime" BO_ 771 200;
BA_ "GenMsgCycleTimeFast" BO_ 771 100;
BA_ "GenMsgCycleTime" BO_ 770 200;
BA_ "GenMsgCycleTimeFast" BO_ 770 100;
BA_ "GenMsgCycleTime" BO_ 769 200;
BA_ "GenMsgCycleTimeFast" BO_ 769 100;
BA_ "GenMsgCycleTime" BO_ 778 30000;
BA_ "GenMsgCycleTimeFast" BO_ 778 100;
BA_ "GenMsgCycleTime" BO_ 777 30000;
BA_ "GenMsgCycleTimeFast" BO_ 777 100;
BA_ "GenMsgCycleTime" BO_ 776 30000;
BA_ "GenMsgCycleTimeFast" BO_ 776 100;
BA_ "GenMsgCycleTime" BO_ 775 30000;
BA_ "GenMsgCycleTimeFast" BO_ 775 100;
BA_ "GenMsgCycleTime" BO_ 768 1000;
BA_ "GenMsgCycleTimeFast" BO_ 768 100;
BA_ "GenMsgCycleTime" BO_ 783 30000;
BA_ "GenMsgCycleTimeFast" BO_ 783 100;
BA_ "GenMsgCycleTime" BO_ 782 30000;
BA_ "GenMsgCycleTimeFast" BO_ 782 100;
BA_ "GenMsgCycleTime" BO_ 1827 100;
BA_ "GenMsgCycleTimeFast" BO_ 1827 100;
BA_ "GenMsgCycleTime" BO_ 1826 100;
BA_ "GenMsgCycleTimeFast" BO_ 1826 100;
BA_ "GenMsgCycleTime" BO_ 1825 100;
BA_ "GenMsgCycleTimeFast" BO_ 1825 100;
BA_ "GenMsgCycleTime" BO_ 1869 200;
BA_ "GenMsgCycleTimeFast" BO_ 1869 100;
BA_ "GenMsgCycleTime" BO_ 1200 14;
BA_ "GenMsgCycleTimeFast" BO_ 1200 100;
BA_ "GenMsgCycleTime" BO_ 528 14;
BA_ "GenMsgCycleTimeFast" BO_ 528 100;
BA_ "GenSigCycleTime" SG_ 1120 RIL_Request 100;
BA_ "GenSigCycleTimeActive" SG_ 1120 RIL_Request 100;
BA_ "GenSigCycleTime" SG_ 35 RCM_FuelCutOff 200;
BA_ "GenSigCycleTimeActive" SG_ 35 RCM_FuelCutOff 200;
BA_ "GenSigStartValue" SG_ 35 RCM_FuelCutOff 2;
BA_ "GenSigCycleTime" SG_ 35 RCM_EventNotification 200;
BA_ "GenSigCycleTimeActive" SG_ 35 RCM_EventNotification 200;
BA_ "GenSigCycleTime" SG_ 1872 RAC_SW_minor 5000;
BA_ "GenSigCycleTimeActive" SG_ 1872 RAC_SW_minor 5000;
BA_ "GenSigCycleTime" SG_ 1872 RAC_HW_minor 5000;
BA_ "GenSigCycleTimeActive" SG_ 1872 RAC_HW_minor 5000;
BA_ "GenSigCycleTime" SG_ 1872 RAC_SW_patch 5000;
BA_ "GenSigCycleTimeActive" SG_ 1872 RAC_SW_patch 5000;
BA_ "GenSigCycleTime" SG_ 1872 RAC_SW_major 5000;
BA_ "GenSigCycleTimeActive" SG_ 1872 RAC_SW_major 5000;
BA_ "GenSigCycleTime" SG_ 1872 RAC_HW_major 5000;
BA_ "GenSigCycleTimeActive" SG_ 1872 RAC_HW_major 5000;
BA_ "GenSigCycleTime" SG_ 1874 VIN_Data 10000;
BA_ "GenSigCycleTimeActive" SG_ 1874 VIN_Data 10000;
BA_ "GenSigCycleTime" SG_ 1874 VIN_Index 10000;
BA_ "GenSigCycleTimeActive" SG_ 1874 VIN_Index 10000;
BA_ "GenSigCycleTime" SG_ 1027 TimeHour 1000;
BA_ "GenSigCycleTimeActive" SG_ 1027 TimeHour 1000;
BA_ "GenSigCycleTime" SG_ 1027 TimeDayInMonth 1000;
BA_ "GenSigCycleTimeActive" SG_ 1027 TimeDayInMonth 1000;
BA_ "GenSigCycleTime" SG_ 1027 TimeMonth 1000;
BA_ "GenSigCycleTimeActive" SG_ 1027 TimeMonth 1000;
BA_ "GenSigCycleTime" SG_ 1027 TimeDayInWeek 1000;
BA_ "GenSigCycleTimeActive" SG_ 1027 TimeDayInWeek 1000;
BA_ "GenSigCycleTime" SG_ 1027 TimeSecond 1000;
BA_ "GenSigCycleTimeActive" SG_ 1027 TimeSecond 1000;
BA_ "GenSigCycleTime" SG_ 1027 TimeMinute 1000;
BA_ "GenSigCycleTimeActive" SG_ 1027 TimeMinute 1000;
BA_ "GenSigCycleTime" SG_ 1027 TimeYear 1000;
BA_ "GenSigCycleTimeActive" SG_ 1027 TimeYear 1000;
BA_ "GenSigCycleTime" SG_ 1025 MemoryManagementStatus 500;
BA_ "GenSigCycleTimeActive" SG_ 1025 MemoryManagementStatus 500;
BA_ "GenSigCycleTime" SG_ 1025 AirbagLampDriver 500;
BA_ "GenSigCycleTimeActive" SG_ 1025 AirbagLampDriver 500;
BA_ "GenSigCycleTime" SG_ 1025 HelpDeskLampStatus 500;
BA_ "GenSigCycleTimeActive" SG_ 1025 HelpDeskLampStatus 500;
BA_ "GenSigCycleTime" SG_ 1025 PhoneCallStatus 500;
BA_ "GenSigCycleTimeActive" SG_ 1025 PhoneCallStatus 500;
BA_ "GenSigCycleTime" SG_ 1025 GPRSStatus 500;
BA_ "GenSigCycleTimeActive" SG_ 1025 GPRSStatus 500;
BA_ "GenSigCycleTime" SG_ 1025 InCommunication 500;
BA_ "GenSigCycleTimeActive" SG_ 1025 InCommunication 500;
BA_ "GenSigCycleTime" SG_ 1025 GPSAntennaStatus 500;
BA_ "GenSigCycleTimeActive" SG_ 1025 GPSAntennaStatus 500;
BA_ "GenSigCycleTime" SG_ 1025 CarState 500;
BA_ "GenSigCycleTimeActive" SG_ 1025 CarState 500;
BA_ "GenSigCycleTime" SG_ 1025 BluetoothConnection 500;
BA_ "GenSigCycleTimeActive" SG_ 1025 BluetoothConnection 500;
BA_ "GenSigCycleTime" SG_ 1025 BluetoothStatus 500;
BA_ "GenSigCycleTimeActive" SG_ 1025 BluetoothStatus 500;
BA_ "GenSigCycleTime" SG_ 1025 GPSStatus 500;
BA_ "GenSigCycleTimeActive" SG_ 1025 GPSStatus 500;
BA_ "GenSigCycleTime" SG_ 1025 ContactKey 500;
BA_ "GenSigCycleTimeActive" SG_ 1025 ContactKey 500;
BA_ "GenSigCycleTime" SG_ 1025 SIMCardStatus 500;
BA_ "GenSigCycleTimeActive" SG_ 1025 SIMCardStatus 500;
BA_ "GenSigCycleTime" SG_ 1025 HelpDeskRequest 500;
BA_ "GenSigCycleTimeActive" SG_ 1025 HelpDeskRequest 500;
BA_ "GenSigCycleTime" SG_ 1025 GSMStatus 500;
BA_ "GenSigCycleTimeActive" SG_ 1025 GSMStatus 500;
BA_ "GenSigCycleTime" SG_ 1025 GPSModuleStatus 500;
BA_ "GenSigCycleTimeActive" SG_ 1025 GPSModuleStatus 500;
BA_ "GenSigCycleTime" SG_ 1025 CSQQuality 500;
BA_ "GenSigCycleTimeActive" SG_ 1025 CSQQuality 500;
BA_ "GenSigCycleTime" SG_ 1025 ConnectedToServer 500;
BA_ "GenSigCycleTimeActive" SG_ 1025 ConnectedToServer 500;
BA_ "GenSigCycleTime" SG_ 1025 AirbagLampStatus 500;
BA_ "GenSigCycleTimeActive" SG_ 1025 AirbagLampStatus 500;
BA_ "GenSigCycleTime" SG_ 1025 HelpDeskButtonStatus 500;
BA_ "GenSigCycleTimeActive" SG_ 1025 HelpDeskButtonStatus 500;
BA_ "GenSigCycleTime" SG_ 1025 GSMModuleStatus 500;
BA_ "GenSigCycleTimeActive" SG_ 1025 GSMModuleStatus 500;
BA_ "GenSigCycleTime" SG_ 1025 AssistNumberProgrammed 500;
BA_ "GenSigCycleTimeActive" SG_ 1025 AssistNumberProgrammed 500;
BA_ "GenSigCycleTime" SG_ 1025 EPOStatus 500;
BA_ "GenSigCycleTimeActive" SG_ 1025 EPOStatus 500;
BA_ "GenSigCycleTime" SG_ 1025 CrashEvent 500;
BA_ "GenSigCycleTimeActive" SG_ 1025 CrashEvent 500;
BA_ "GenSigCycleTime" SG_ 1025 GPSSatellites 500;
BA_ "GenSigCycleTimeActive" SG_ 1025 GPSSatellites 500;
BA_ "GenSigCycleTime" SG_ 1025 SoundLevel 500;
BA_ "GenSigCycleTimeActive" SG_ 1025 SoundLevel 500;
BA_ "GenSigCycleTime" SG_ 1030 RACSerialNumber2 30000;
BA_ "GenSigCycleTimeActive" SG_ 1030 RACSerialNumber2 100;
BA_ "GenSigCycleTime" SG_ 1029 RACSerialNumber1 30000;
BA_ "GenSigCycleTimeActive" SG_ 1029 RACSerialNumber1 100;
BA_ "GenSigCycleTime" SG_ 1920 PhoneNumber 10000;
BA_ "GenSigCycleTimeActive" SG_ 1920 PhoneNumber 10000;
BA_ "GenSigCycleTime" SG_ 1920 PhoneIndex 10000;
BA_ "GenSigCycleTimeActive" SG_ 1920 PhoneIndex 10000;
BA_ "GenSigCycleTime" SG_ 1028 Odometer 1000;
BA_ "GenSigCycleTimeActive" SG_ 1028 Odometer 1000;
BA_ "GenSigCycleTime" SG_ 1028 RACSupplyVoltage 100;
BA_ "GenSigCycleTimeActive" SG_ 1028 RACSupplyVoltage 100;
BA_ "GenSigCycleTime" SG_ 1904 HistoricFlag_SIMNotInserted 5000;
BA_ "GenSigCycleTimeActive" SG_ 1904 HistoricFlag_SIMNotInserted 5000;
BA_ "GenSigCycleTime" SG_ 1904 ErrorFlag_GPSAntennaOC 5000;
BA_ "GenSigCycleTimeActive" SG_ 1904 ErrorFlag_GPSAntennaOC 5000;
BA_ "GenSigCycleTime" SG_ 1904 HistoricFlag_WatchdogReboot 5000;
BA_ "GenSigCycleTimeActive" SG_ 1904 HistoricFlag_WatchdogReboot 5000;
BA_ "GenSigCycleTime" SG_ 1904 HistoricFlag_GPSNotResponding 5000;
BA_ "GenSigCycleTimeActive" SG_ 1904 HistoricFlag_GPSNotResponding 5000;
BA_ "GenSigCycleTime" SG_ 1904 ErrorFlag_SIMNotInserted 5000;
BA_ "GenSigCycleTimeActive" SG_ 1904 ErrorFlag_SIMNotInserted 5000;
BA_ "GenSigCycleTime" SG_ 1904 ErrorFlag_GPSAntennaSCGND 5000;
BA_ "GenSigCycleTimeActive" SG_ 1904 ErrorFlag_GPSAntennaSCGND 5000;
BA_ "GenSigCycleTime" SG_ 1904 HistoricFlag_GSMNotResponding 5000;
BA_ "GenSigCycleTimeActive" SG_ 1904 HistoricFlag_GSMNotResponding 5000;
BA_ "GenSigCycleTime" SG_ 1904 HistoricFlag_FlashMemoryError 5000;
BA_ "GenSigCycleTimeActive" SG_ 1904 HistoricFlag_FlashMemoryError 5000;
BA_ "GenSigCycleTime" SG_ 1904 ErrorFlag_VeryLowBattery 5000;
BA_ "GenSigCycleTimeActive" SG_ 1904 ErrorFlag_VeryLowBattery 5000;
BA_ "GenSigCycleTime" SG_ 1904 ErrorFlag_HelpdeskNotPrg 5000;
BA_ "GenSigCycleTimeActive" SG_ 1904 ErrorFlag_HelpdeskNotPrg 5000;
BA_ "GenSigCycleTime" SG_ 1904 ErrorFlag_SIMRefused 5000;
BA_ "GenSigCycleTimeActive" SG_ 1904 ErrorFlag_SIMRefused 5000;
BA_ "GenSigCycleTime" SG_ 1904 ErrorFlag_PINError 5000;
BA_ "GenSigCycleTimeActive" SG_ 1904 ErrorFlag_PINError 5000;
BA_ "GenSigCycleTime" SG_ 1904 ErrorFlag_FlashMemoryError 5000;
BA_ "GenSigCycleTimeActive" SG_ 1904 ErrorFlag_FlashMemoryError 5000;
BA_ "GenSigCycleTime" SG_ 1904 ErrorFlag_LowBattery 5000;
BA_ "GenSigCycleTimeActive" SG_ 1904 ErrorFlag_LowBattery 5000;
BA_ "GenSigCycleTime" SG_ 1904 HistoricFlag_LastDownloadFailed 5000;
BA_ "GenSigCycleTimeActive" SG_ 1904 HistoricFlag_LastDownloadFailed 5000;
BA_ "GenSigCycleTime" SG_ 1904 ErrorFlag_WatchdogReboot 5000;
BA_ "GenSigCycleTimeActive" SG_ 1904 ErrorFlag_WatchdogReboot 5000;
BA_ "GenSigCycleTime" SG_ 1904 HistoricFlag_PINError 5000;
BA_ "GenSigCycleTimeActive" SG_ 1904 HistoricFlag_PINError 5000;
BA_ "GenSigCycleTime" SG_ 1904 ErrorFlag_GPSNotResponding 5000;
BA_ "GenSigCycleTimeActive" SG_ 1904 ErrorFlag_GPSNotResponding 5000;
BA_ "GenSigCycleTime" SG_ 1904 HistoricFlag_VeryLowBattery 5000;
BA_ "GenSigCycleTimeActive" SG_ 1904 HistoricFlag_VeryLowBattery 5000;
BA_ "GenSigCycleTime" SG_ 1904 HistoricFlag_LowBattery 5000;
BA_ "GenSigCycleTimeActive" SG_ 1904 HistoricFlag_LowBattery 5000;
BA_ "GenSigCycleTime" SG_ 1904 HistoricFlag_BlueNotResponding 5000;
BA_ "GenSigCycleTimeActive" SG_ 1904 HistoricFlag_BlueNotResponding 5000;
BA_ "GenSigCycleTime" SG_ 1904 ErrorFlag_BlueNotResponding 5000;
BA_ "GenSigCycleTimeActive" SG_ 1904 ErrorFlag_BlueNotResponding 5000;
BA_ "GenSigCycleTime" SG_ 1904 ErrorFlag_LastDownloadFailed 5000;
BA_ "GenSigCycleTimeActive" SG_ 1904 ErrorFlag_LastDownloadFailed 5000;
BA_ "GenSigCycleTime" SG_ 1904 HistoricFlag_SIMRefused 5000;
BA_ "GenSigCycleTimeActive" SG_ 1904 HistoricFlag_SIMRefused 5000;
BA_ "GenSigCycleTime" SG_ 1904 ErrorFlag_GSMNotResponding 5000;
BA_ "GenSigCycleTimeActive" SG_ 1904 ErrorFlag_GSMNotResponding 5000;
BA_ "GenSigCycleTime" SG_ 1904 HistoricFlag_GPSAntennaOC 5000;
BA_ "GenSigCycleTimeActive" SG_ 1904 HistoricFlag_GPSAntennaOC 5000;
BA_ "GenSigCycleTime" SG_ 1904 HistoricFlag_GPSAntennaSCGND 5000;
BA_ "GenSigCycleTimeActive" SG_ 1904 HistoricFlag_GPSAntennaSCGND 5000;
BA_ "GenSigCycleTime" SG_ 1904 HistoricFlag_HelpDeskNotPrg 5000;
BA_ "GenSigCycleTimeActive" SG_ 1904 HistoricFlag_HelpDeskNotPrg 5000;
BA_ "GenSigCycleTime" SG_ 1026 CarSharingButtonStatus 500;
BA_ "GenSigCycleTimeActive" SG_ 1026 CarSharingButtonStatus 500;
BA_ "GenSigCycleTime" SG_ 1026 CarSharingAntitheft 100;
BA_ "GenSigCycleTimeActive" SG_ 1026 CarSharingAntitheft 100;
BA_ "GenSigCycleTime" SG_ 1026 CarSharingMode 500;
BA_ "GenSigCycleTimeActive" SG_ 1026 CarSharingMode 500;
BA_ "GenSigCycleTime" SG_ 1026 CarSharingState 500;
BA_ "GenSigCycleTimeActive" SG_ 1026 CarSharingState 500;
BA_ "GenSigCycleTime" SG_ 1026 CarSharingLEDStatus 500;
BA_ "GenSigCycleTimeActive" SG_ 1026 CarSharingLEDStatus 500;
BA_ "GenSigCycleTime" SG_ 1026 CarSharingSelfService 500;
BA_ "GenSigCycleTimeActive" SG_ 1026 CarSharingSelfService 500;
BA_ "GenSigCycleTime" SG_ 785 FastChargeRequest 200;
BA_ "GenSigCycleTimeActive" SG_ 785 FastChargeRequest 200;
BA_ "GenSigCycleTime" SG_ 785 BatteryChargeRequest 200;
BA_ "GenSigCycleTimeActive" SG_ 785 BatteryChargeRequest 200;
BA_ "GenSigCycleTime" SG_ 785 AvailableMainsCurrent 200;
BA_ "GenSigCycleTimeActive" SG_ 785 AvailableMainsCurrent 200;
BA_ "GenSigCycleTime" SG_ 514 MotorSpeed 10;
BA_ "GenSigCycleTimeActive" SG_ 514 MotorSpeed 10;
BA_ "GenSigCycleTime" SG_ 514 BrakeLightSwitch 10;
BA_ "GenSigCycleTimeActive" SG_ 514 BrakeLightSwitch 10;
BA_ "GenSigCycleTime" SG_ 514 DriverTorqueRequest 10;
BA_ "GenSigCycleTimeActive" SG_ 514 DriverTorqueRequest 10;
BA_ "GenSigCycleTime" SG_ 514 MotorTorqueInsDenied 10;
BA_ "GenSigCycleTimeActive" SG_ 514 MotorTorqueInsDenied 10;
BA_ "GenSigCycleTime" SG_ 514 MotorActualTorque 10;
BA_ "GenSigCycleTimeActive" SG_ 514 MotorActualTorque 10;
BA_ "GenSigCycleTime" SG_ 514 PCUFault 10;
BA_ "GenSigCycleTimeActive" SG_ 514 PCUFault 10;
BA_ "GenSigCycleTime" SG_ 514 AcceleratorPedalPosition 10;
BA_ "GenSigCycleTimeActive" SG_ 514 AcceleratorPedalPosition 10;
BA_ "GenSigCycleTime" SG_ 514 TIMStatus 10;
BA_ "GenSigCycleTimeActive" SG_ 514 TIMStatus 10;
BA_ "GenSigCycleTime" SG_ 595 SecurityID_2 100;
BA_ "GenSigCycleTimeActive" SG_ 595 SecurityID_2 100;
BA_ "GenSigCycleTime" SG_ 594 SecurityID_1 100;
BA_ "GenSigCycleTimeActive" SG_ 594 SecurityID_1 100;
BA_ "GenSigCycleTime" SG_ 784 TIM_Status 200;
BA_ "GenSigCycleTimeActive" SG_ 784 TIM_Status 200;
BA_ "GenSigCycleTime" SG_ 784 Charger_Status 200;
BA_ "GenSigCycleTimeActive" SG_ 784 Charger_Status 200;
BA_ "GenSigCycleTime" SG_ 784 DC_DC_Status 200;
BA_ "GenSigCycleTimeActive" SG_ 784 DC_DC_Status 200;
BA_ "GenSigCycleTime" SG_ 784 PCU_Fault 200;
BA_ "GenSigCycleTimeActive" SG_ 784 PCU_Fault 200;
BA_ "GenSigCycleTime" SG_ 784 BroadcastMode 200;
BA_ "GenSigCycleTimeActive" SG_ 784 BroadcastMode 200;
BA_ "GenSigCycleTime" SG_ 849 ChargerRequest 100;
BA_ "GenSigCycleTimeActive" SG_ 849 ChargerRequest 100;
BA_ "GenSigCycleTime" SG_ 849 ChargerAssignedID 100;
BA_ "GenSigCycleTimeActive" SG_ 849 ChargerAssignedID 100;
BA_ "GenSigCycleTime" SG_ 613 SpeedIndication 200;
BA_ "GenSigCycleTimeActive" SG_ 613 SpeedIndication 200;
BA_ "GenSigCycleTime" SG_ 613 CustomerDODIndication 200;
BA_ "GenSigCycleTimeActive" SG_ 613 CustomerDODIndication 200;
BA_ "GenSigCycleTime" SG_ 613 EconometerIndication 200;
BA_ "GenSigCycleTimeActive" SG_ 613 EconometerIndication 200;
BA_ "GenSigCycleTime" SG_ 612 PASEnable 200;
BA_ "GenSigCycleTimeActive" SG_ 612 PASEnable 200;
BA_ "GenSigCycleTime" SG_ 612 ESPIndication 200;
BA_ "GenSigCycleTimeActive" SG_ 612 ESPIndication 200;
BA_ "GenSigCycleTime" SG_ 612 PowerLimitIndication 200;
BA_ "GenSigCycleTimeActive" SG_ 612 PowerLimitIndication 200;
BA_ "GenSigCycleTime" SG_ 612 EconomyIndication 200;
BA_ "GenSigCycleTimeActive" SG_ 612 EconomyIndication 200;
BA_ "GenSigCycleTime" SG_ 612 PCUESPSoftware 200;
BA_ "GenSigCycleTimeActive" SG_ 612 PCUESPSoftware 200;
BA_ "GenSigCycleTime" SG_ 612 ABSWarningIndication 200;
BA_ "GenSigCycleTimeActive" SG_ 612 ABSWarningIndication 200;
BA_ "GenSigCycleTime" SG_ 612 ElectricHzIndication 200;
BA_ "GenSigCycleTimeActive" SG_ 612 ElectricHzIndication 200;
BA_ "GenSigCycleTime" SG_ 612 BrakeWarningIndication 200;
BA_ "GenSigCycleTimeActive" SG_ 612 BrakeWarningIndication 200;
BA_ "GenSigCycleTime" SG_ 612 OvertempIndication 200;
BA_ "GenSigCycleTimeActive" SG_ 612 OvertempIndication 200;
BA_ "GenSigCycleTime" SG_ 612 NeutralIndication 200;
BA_ "GenSigCycleTimeActive" SG_ 612 NeutralIndication 200;
BA_ "GenSigCycleTime" SG_ 612 MILIndication 200;
BA_ "GenSigCycleTimeActive" SG_ 612 MILIndication 200;
BA_ "GenSigCycleTime" SG_ 612 PowertrainGeneration 200;
BA_ "GenSigCycleTimeActive" SG_ 612 PowertrainGeneration 200;
BA_ "GenSigCycleTime" SG_ 612 ChargingIndication 200;
BA_ "GenSigCycleTimeActive" SG_ 612 ChargingIndication 200;
BA_ "GenSigCycleTime" SG_ 612 AuxiliaryBatteryLowIndication 200;
BA_ "GenSigCycleTimeActive" SG_ 612 AuxiliaryBatteryLowIndication 200;
BA_ "GenSigCycleTime" SG_ 612 DriveEnableIndication 200;
BA_ "GenSigCycleTimeActive" SG_ 612 DriveEnableIndication 200;
BA_ "GenSigCycleTime" SG_ 612 PCUPTCReady 200;
BA_ "GenSigCycleTimeActive" SG_ 612 PCUPTCReady 200;
BA_ "GenSigCycleTime" SG_ 612 OnPlugIndication 200;
BA_ "GenSigCycleTimeActive" SG_ 612 OnPlugIndication 200;
BA_ "GenSigCycleTime" SG_ 612 GearPosition 200;
BA_ "GenSigCycleTimeActive" SG_ 612 GearPosition 200;
BA_ "GenSigCycleTime" SG_ 612 ParkIndication 200;
BA_ "GenSigCycleTimeActive" SG_ 612 ParkIndication 200;
BA_ "GenSigCycleTime" SG_ 612 ReverseIndication 200;
BA_ "GenSigCycleTimeActive" SG_ 612 ReverseIndication 200;
BA_ "GenSigCycleTime" SG_ 612 LowSOCIndication 200;
BA_ "GenSigCycleTimeActive" SG_ 612 LowSOCIndication 200;
BA_ "GenSigCycleTime" SG_ 612 PilotSignalPresent 200;
BA_ "GenSigCycleTimeActive" SG_ 612 PilotSignalPresent 200;
BA_ "GenSigCycleTime" SG_ 612 DriveIndication 200;
BA_ "GenSigCycleTimeActive" SG_ 612 DriveIndication 200;
BA_ "GenSigCycleTime" SG_ 611 SLI_Voltage 500;
BA_ "GenSigCycleTimeActive" SG_ 611 SLI_Voltage 500;
BA_ "GenSigCycleTime" SG_ 611 Mains_Voltage 500;
BA_ "GenSigCycleTimeActive" SG_ 611 Mains_Voltage 500;
BA_ "GenSigCycleTime" SG_ 611 SLI_AmbientTemperature 500;
BA_ "GenSigCycleTimeActive" SG_ 611 SLI_AmbientTemperature 500;
BA_ "GenSigCycleTime" SG_ 611 VehicleSpeedCounter 500;
BA_ "GenSigCycleTimeActive" SG_ 611 VehicleSpeedCounter 500;
BA_ "GenSigCycleTime" SG_ 611 Mains_Current 500;
BA_ "GenSigCycleTimeActive" SG_ 611 Mains_Current 500;
BA_ "GenSigCycleTime" SG_ 611 VehicleSpeed 500;
BA_ "GenSigCycleTimeActive" SG_ 611 VehicleSpeed 500;
BA_ "GenSigCycleTime" SG_ 593 AntiscanMode 100;
BA_ "GenSigCycleTimeActive" SG_ 593 AntiscanMode 100;
BA_ "GenSigCycleTime" SG_ 593 ChallengeRequestActive 100;
BA_ "GenSigCycleTimeActive" SG_ 593 ChallengeRequestActive 100;
BA_ "GenSigCycleTime" SG_ 593 ChallengeRequest 100;
BA_ "GenSigCycleTimeActive" SG_ 593 ChallengeRequest 100;
BA_ "GenSigCycleTime" SG_ 593 KeyRequest 100;
BA_ "GenSigCycleTimeActive" SG_ 593 KeyRequest 100;
BA_ "GenSigCycleTime" SG_ 593 SecurityIDActive 100;
BA_ "GenSigCycleTimeActive" SG_ 593 SecurityIDActive 100;
BA_ "GenSigCycleTime" SG_ 593 VehicleStatus 100;
BA_ "GenSigCycleTimeActive" SG_ 593 VehicleStatus 100;
BA_ "GenSigCycleTime" SG_ 593 LEDFlashError 100;
BA_ "GenSigCycleTimeActive" SG_ 593 LEDFlashError 100;
BA_ "GenSigCycleTime" SG_ 850 ChargerOutputVoltageLimit 200;
BA_ "GenSigCycleTimeActive" SG_ 850 ChargerOutputVoltageLimit 200;
BA_ "GenSigCycleTime" SG_ 850 ChargerOutputPowerDemand 200;
BA_ "GenSigCycleTimeActive" SG_ 850 ChargerOutputPowerDemand 200;
BA_ "GenSigCycleTime" SG_ 850 EnableCharger 200;
BA_ "GenSigCycleTimeActive" SG_ 850 EnableCharger 200;
BA_ "GenSigCycleTime" SG_ 850 ReceiverID_1 200;
BA_ "GenSigCycleTimeActive" SG_ 850 ReceiverID_1 200;
BA_ "GenSigCycleTime" SG_ 277 PAS_SupplierApplication 100;
BA_ "GenSigCycleTimeActive" SG_ 277 PAS_SupplierApplication 100;
BA_ "GenSigCycleTime" SG_ 277 PAS_SoftwareVersion 100;
BA_ "GenSigCycleTimeActive" SG_ 277 PAS_SoftwareVersion 100;
BA_ "GenSigCycleTime" SG_ 277 PAS_SoftwareIssue 100;
BA_ "GenSigCycleTimeActive" SG_ 277 PAS_SoftwareIssue 100;
BA_ "GenSigCycleTime" SG_ 277 PAS_VersionMonth 100;
BA_ "GenSigCycleTimeActive" SG_ 277 PAS_VersionMonth 100;
BA_ "GenSigCycleTime" SG_ 277 PAS_VersionDay 100;
BA_ "GenSigCycleTimeActive" SG_ 277 PAS_VersionDay 100;
BA_ "GenSigCycleTime" SG_ 277 PAS_VersionYear 100;
BA_ "GenSigCycleTimeActive" SG_ 277 PAS_VersionYear 100;
BA_ "GenSigCycleTime" SG_ 277 PAS_SystemVersion 100;
BA_ "GenSigCycleTimeActive" SG_ 277 PAS_SystemVersion 100;
BA_ "GenSigCycleTime" SG_ 277 PAS_CalibrationIssue 100;
BA_ "GenSigCycleTimeActive" SG_ 277 PAS_CalibrationIssue 100;
BA_ "GenSigCycleTime" SG_ 1173 PAS_Status 100;
BA_ "GenSigCycleTimeActive" SG_ 1173 PAS_Status 100;
BA_ "GenSigCycleTime" SG_ 392 ESPFrontRightWheelSpeed 10;
BA_ "GenSigCycleTimeActive" SG_ 392 ESPFrontRightWheelSpeed 10;
BA_ "GenSigCycleTime" SG_ 392 ESPRearLeftWheelSpeed 10;
BA_ "GenSigCycleTimeActive" SG_ 392 ESPRearLeftWheelSpeed 10;
BA_ "GenSigCycleTime" SG_ 392 ESPRearRightWheelSpeed 10;
BA_ "GenSigCycleTimeActive" SG_ 392 ESPRearRightWheelSpeed 10;
BA_ "GenSigCycleTime" SG_ 392 ESPFrontLeftWheelSpeed 10;
BA_ "GenSigCycleTimeActive" SG_ 392 ESPFrontLeftWheelSpeed 10;
BA_ "GenSigCycleTime" SG_ 391 SASState 10;
BA_ "GenSigCycleTimeActive" SG_ 391 SASState 10;
BA_ "GenSigCycleTime" SG_ 391 SteeringAngle 10;
BA_ "GenSigCycleTimeActive" SG_ 391 SteeringAngle 10;
BA_ "GenSigCycleTime" SG_ 391 SteeringAngleSpeed 10;
BA_ "GenSigCycleTimeActive" SG_ 391 SteeringAngleSpeed 10;
BA_ "GenSigCycleTime" SG_ 391 SASCal 10;
BA_ "GenSigCycleTimeActive" SG_ 391 SASCal 10;
BA_ "GenSigCycleTime" SG_ 391 SASTrim 10;
BA_ "GenSigCycleTimeActive" SG_ 391 SASTrim 10;
BA_ "GenSigCycleTime" SG_ 390 ESPSystemStatus 10;
BA_ "GenSigCycleTimeActive" SG_ 390 ESPSystemStatus 10;
BA_ "GenSigCycleTime" SG_ 390 EBDStatus 10;
BA_ "GenSigCycleTimeActive" SG_ 390 EBDStatus 10;
BA_ "GenSigCycleTime" SG_ 390 ESPStatus 10;
BA_ "GenSigCycleTimeActive" SG_ 390 ESPStatus 10;
BA_ "GenSigCycleTime" SG_ 390 ABSStatus 10;
BA_ "GenSigCycleTimeActive" SG_ 390 ABSStatus 10;
BA_ "GenSigCycleTime" SG_ 390 BrakePressure 10;
BA_ "GenSigCycleTimeActive" SG_ 390 BrakePressure 10;
BA_ "GenSigCycleTime" SG_ 390 ESPLamp 10;
BA_ "GenSigCycleTimeActive" SG_ 390 ESPLamp 10;
BA_ "GenSigCycleTime" SG_ 390 ESPTorqueIntervention 10;
BA_ "GenSigCycleTimeActive" SG_ 390 ESPTorqueIntervention 10;
BA_ "GenSigCycleTime" SG_ 390 ABSLamp 10;
BA_ "GenSigCycleTimeActive" SG_ 390 ABSLamp 10;
BA_ "GenSigCycleTime" SG_ 390 ESPVehicleSpeed 10;
BA_ "GenSigCycleTimeActive" SG_ 390 ESPVehicleSpeed 10;
BA_ "GenSigCycleTime" SG_ 390 ESPTorqueDecReq 10;
BA_ "GenSigCycleTimeActive" SG_ 390 ESPTorqueDecReq 10;
BA_ "GenSigCycleTime" SG_ 390 EBDLamp 10;
BA_ "GenSigCycleTimeActive" SG_ 390 EBDLamp 10;
BA_ "GenSigCycleTime" SG_ 390 ESPTorqueIncReq 10;
BA_ "GenSigCycleTimeActive" SG_ 390 ESPTorqueIncReq 10;
BA_ "GenSigCycleTime" SG_ 390 ESPTorqueRequest 10;
BA_ "GenSigCycleTimeActive" SG_ 390 ESPTorqueRequest 10;
BA_ "GenSigCycleTime" SG_ 852 RectifierID_2 200;
BA_ "GenSigCycleTimeActive" SG_ 852 RectifierID_2 200;
BA_ "GenSigCycleTime" SG_ 852 ChargerOutTemperature 200;
BA_ "GenSigCycleTimeActive" SG_ 852 ChargerOutTemperature 200;
BA_ "GenSigCycleTime" SG_ 852 ChargerInTemperature 200;
BA_ "GenSigCycleTimeActive" SG_ 852 ChargerInTemperature 200;
BA_ "GenSigCycleTime" SG_ 852 ChargerMainsVoltage 200;
BA_ "GenSigCycleTimeActive" SG_ 852 ChargerMainsVoltage 200;
BA_ "GenSigCycleTime" SG_ 852 ChargerAvailablePowerPercentage 200;
BA_ "GenSigCycleTimeActive" SG_ 852 ChargerAvailablePowerPercentage 200;
BA_ "GenSigCycleTime" SG_ 852 ChargerNominalPower 200;
BA_ "GenSigCycleTimeActive" SG_ 852 ChargerNominalPower 200;
BA_ "GenSigCycleTime" SG_ 851 ChargerMainsCurrent 200;
BA_ "GenSigCycleTimeActive" SG_ 851 ChargerMainsCurrent 200;
BA_ "GenSigCycleTime" SG_ 851 ChargerDCVoltage 200;
BA_ "GenSigCycleTimeActive" SG_ 851 ChargerDCVoltage 200;
BA_ "GenSigCycleTime" SG_ 851 RectifierID_1 200;
BA_ "GenSigCycleTimeActive" SG_ 851 RectifierID_1 200;
BA_ "GenSigCycleTime" SG_ 851 ChargerDCCurrent 200;
BA_ "GenSigCycleTimeActive" SG_ 851 ChargerDCCurrent 200;
BA_ "GenSigCycleTime" SG_ 851 ChargerStatus 200;
BA_ "GenSigCycleTimeActive" SG_ 851 ChargerStatus 200;
BA_ "GenSigCycleTime" SG_ 848 LogInRequest 1000;
BA_ "GenSigCycleTimeActive" SG_ 848 LogInRequest 1000;
BA_ "GenSigCycleTime" SG_ 853 CommunicationFailure 200;
BA_ "GenSigCycleTimeActive" SG_ 853 CommunicationFailure 200;
BA_ "GenSigCycleTime" SG_ 853 LowMainsError 200;
BA_ "GenSigCycleTimeActive" SG_ 853 LowMainsError 200;
BA_ "GenSigCycleTime" SG_ 853 DCUndervoltageError 200;
BA_ "GenSigCycleTimeActive" SG_ 853 DCUndervoltageError 200;
BA_ "GenSigCycleTime" SG_ 853 CurrentLimitError 200;
BA_ "GenSigCycleTimeActive" SG_ 853 CurrentLimitError 200;
BA_ "GenSigCycleTime" SG_ 853 HighTemperatureShutdownError 200;
BA_ "GenSigCycleTimeActive" SG_ 853 HighTemperatureShutdownError 200;
BA_ "GenSigCycleTime" SG_ 853 HighMainsError 200;
BA_ "GenSigCycleTimeActive" SG_ 853 HighMainsError 200;
BA_ "GenSigCycleTime" SG_ 853 DCOvervoltageError 200;
BA_ "GenSigCycleTimeActive" SG_ 853 DCOvervoltageError 200;
BA_ "GenSigCycleTime" SG_ 853 ControllerCommunicationError 200;
BA_ "GenSigCycleTimeActive" SG_ 853 ControllerCommunicationError 200;
BA_ "GenSigCycleTime" SG_ 853 ModuleFailureError 200;
BA_ "GenSigCycleTimeActive" SG_ 853 ModuleFailureError 200;
BA_ "GenSigCycleTime" SG_ 853 RectifierID_3 200;
BA_ "GenSigCycleTimeActive" SG_ 853 RectifierID_3 200;
BA_ "GenSigCycleTime" SG_ 853 LowTemperatureShutdownError 200;
BA_ "GenSigCycleTimeActive" SG_ 853 LowTemperatureShutdownError 200;
BA_ "GenSigCycleTime" SG_ 1032 CDCMFrontDemistSwitch 500;
BA_ "GenSigCycleTimeActive" SG_ 1032 CDCMFrontDemistSwitch 500;
BA_ "GenSigCycleTime" SG_ 1032 CDCMRearDemistSwitch 500;
BA_ "GenSigCycleTimeActive" SG_ 1032 CDCMRearDemistSwitch 500;
BA_ "GenSigCycleTime" SG_ 1032 CDCMHWVersion 500;
BA_ "GenSigCycleTimeActive" SG_ 1032 CDCMHWVersion 500;
BA_ "GenSigCycleTime" SG_ 1032 ACPresent 500;
BA_ "GenSigCycleTimeActive" SG_ 1032 ACPresent 500;
BA_ "GenSigCycleTime" SG_ 1032 CDCMKeyRun 500;
BA_ "GenSigCycleTimeActive" SG_ 1032 CDCMKeyRun 500;
BA_ "GenSigCycleTime" SG_ 1032 CDCMWakeUp 500;
BA_ "GenSigCycleTimeActive" SG_ 1032 CDCMWakeUp 500;
BA_ "GenSigCycleTime" SG_ 1032 CDCMSWVersion 500;
BA_ "GenSigCycleTimeActive" SG_ 1032 CDCMSWVersion 500;
BA_ "GenSigCycleTime" SG_ 1032 CDCM12VSupply 500;
BA_ "GenSigCycleTimeActive" SG_ 1032 CDCM12VSupply 500;
BA_ "GenSigCycleTime" SG_ 1032 CDCMHeaterFault 500;
BA_ "GenSigCycleTimeActive" SG_ 1032 CDCMHeaterFault 500;
BA_ "GenSigCycleTime" SG_ 1032 CDCMHVRequest 500;
BA_ "GenSigCycleTimeActive" SG_ 1032 CDCMHVRequest 500;
BA_ "GenSigCycleTime" SG_ 1032 CDCMFrontDemist1 500;
BA_ "GenSigCycleTimeActive" SG_ 1032 CDCMFrontDemist1 500;
BA_ "GenSigCycleTime" SG_ 1032 CDCMCondenserFan 500;
BA_ "GenSigCycleTimeActive" SG_ 1032 CDCMCondenserFan 500;
BA_ "GenSigCycleTime" SG_ 1032 EvaporatorTemperature 500;
BA_ "GenSigCycleTimeActive" SG_ 1032 EvaporatorTemperature 500;
BA_ "GenSigCycleTime" SG_ 1032 CDCMHeaterEnable 500;
BA_ "GenSigCycleTimeActive" SG_ 1032 CDCMHeaterEnable 500;
BA_ "GenSigCycleTime" SG_ 1032 CDCMInverterSupply 500;
BA_ "GenSigCycleTimeActive" SG_ 1032 CDCMInverterSupply 500;
BA_ "GenSigCycleTime" SG_ 1032 CDCMForcedBlower 500;
BA_ "GenSigCycleTimeActive" SG_ 1032 CDCMForcedBlower 500;
BA_ "GenSigCycleTime" SG_ 1032 CDCMFrontDemist2 500;
BA_ "GenSigCycleTimeActive" SG_ 1032 CDCMFrontDemist2 500;
BA_ "GenSigCycleTime" SG_ 1032 HeaterKnobPosition 500;
BA_ "GenSigCycleTimeActive" SG_ 1032 HeaterKnobPosition 500;
BA_ "GenSigCycleTime" SG_ 1032 CDCMRearDemist 500;
BA_ "GenSigCycleTimeActive" SG_ 1032 CDCMRearDemist 500;
BA_ "GenSigCycleTime" SG_ 1032 CDCMOperationState 500;
BA_ "GenSigCycleTimeActive" SG_ 1032 CDCMOperationState 500;
BA_ "GenSigCycleTime" SG_ 1032 CDCMACRequest 500;
BA_ "GenSigCycleTimeActive" SG_ 1032 CDCMACRequest 500;
BA_ "GenSigCycleTime" SG_ 69 PTC_FuelCutOff 200;
BA_ "GenSigCycleTimeActive" SG_ 69 PTC_FuelCutOff 200;
BA_ "GenSigCycleTime" SG_ 1033 KnobPositionTooHigh 500;
BA_ "GenSigCycleTimeActive" SG_ 1033 KnobPositionTooHigh 100;
BA_ "GenSigCycleTime" SG_ 1033 CondenserFanOC 500;
BA_ "GenSigCycleTimeActive" SG_ 1033 CondenserFanOC 100;
BA_ "GenSigCycleTime" SG_ 1033 PTCCommunicationBroken 500;
BA_ "GenSigCycleTimeActive" SG_ 1033 PTCCommunicationBroken 100;
BA_ "GenSigCycleTime" SG_ 1033 RearDemistSC 500;
BA_ "GenSigCycleTimeActive" SG_ 1033 RearDemistSC 100;
BA_ "GenSigCycleTime" SG_ 1033 PTCHVMissing 500;
BA_ "GenSigCycleTimeActive" SG_ 1033 PTCHVMissing 100;
BA_ "GenSigCycleTime" SG_ 1033 HVrequestSC 500;
BA_ "GenSigCycleTimeActive" SG_ 1033 HVrequestSC 100;
BA_ "GenSigCycleTime" SG_ 1033 FrontDemist2OC 500;
BA_ "GenSigCycleTimeActive" SG_ 1033 FrontDemist2OC 100;
BA_ "GenSigCycleTime" SG_ 1033 FluidHeaterFaultLineOld 500;
BA_ "GenSigCycleTimeActive" SG_ 1033 FluidHeaterFaultLineOld 100;
BA_ "GenSigCycleTime" SG_ 1033 ClimateCANTimeout 500;
BA_ "GenSigCycleTimeActive" SG_ 1033 ClimateCANTimeout 100;
BA_ "GenSigCycleTime" SG_ 1033 KnobPositionTooLow 500;
BA_ "GenSigCycleTimeActive" SG_ 1033 KnobPositionTooLow 100;
BA_ "GenSigCycleTime" SG_ 1033 PTCOtherError 500;
BA_ "GenSigCycleTimeActive" SG_ 1033 PTCOtherError 100;
BA_ "GenSigCycleTime" SG_ 1033 HeaterEnableOC 500;
BA_ "GenSigCycleTimeActive" SG_ 1033 HeaterEnableOC 100;
BA_ "GenSigCycleTime" SG_ 1033 HeaterEnableSC 500;
BA_ "GenSigCycleTimeActive" SG_ 1033 HeaterEnableSC 100;
BA_ "GenSigCycleTime" SG_ 1033 CondenserFanSC 500;
BA_ "GenSigCycleTimeActive" SG_ 1033 CondenserFanSC 100;
BA_ "GenSigCycleTime" SG_ 1033 ForcedBlowerOC 500;
BA_ "GenSigCycleTimeActive" SG_ 1033 ForcedBlowerOC 100;
BA_ "GenSigCycleTime" SG_ 1033 InverterSupplyOC 500;
BA_ "GenSigCycleTimeActive" SG_ 1033 InverterSupplyOC 100;
BA_ "GenSigCycleTime" SG_ 1033 FrontDemist1SC 500;
BA_ "GenSigCycleTimeActive" SG_ 1033 FrontDemist1SC 100;
BA_ "GenSigCycleTime" SG_ 1033 BMSSWNotReady 500;
BA_ "GenSigCycleTimeActive" SG_ 1033 BMSSWNotReady 100;
BA_ "GenSigCycleTime" SG_ 1033 ForcedBlowerSC 500;
BA_ "GenSigCycleTimeActive" SG_ 1033 ForcedBlowerSC 100;
BA_ "GenSigCycleTime" SG_ 1033 RearDemistOC 500;
BA_ "GenSigCycleTimeActive" SG_ 1033 RearDemistOC 100;
BA_ "GenSigCycleTime" SG_ 1033 TemperatureSensorSignalTooLow 500;
BA_ "GenSigCycleTimeActive" SG_ 1033 TemperatureSensorSignalTooLow 100;
BA_ "GenSigCycleTime" SG_ 1033 TemperatureSensorSignalTooHigh 500;
BA_ "GenSigCycleTimeActive" SG_ 1033 TemperatureSensorSignalTooHigh 100;
BA_ "GenSigCycleTime" SG_ 1033 InverterSupplySC 500;
BA_ "GenSigCycleTimeActive" SG_ 1033 InverterSupplySC 100;
BA_ "GenSigCycleTime" SG_ 1033 FrontDemist2SC 500;
BA_ "GenSigCycleTimeActive" SG_ 1033 FrontDemist2SC 100;
BA_ "GenSigCycleTime" SG_ 1033 FrontDemist1OC 500;
BA_ "GenSigCycleTimeActive" SG_ 1033 FrontDemist1OC 100;
BA_ "GenSigCycleTime" SG_ 1033 FluidHeaterFaultLineCurrent 500;
BA_ "GenSigCycleTimeActive" SG_ 1033 FluidHeaterFaultLineCurrent 100;
BA_ "GenSigCycleTime" SG_ 1033 PCUSWNotReady 500;
BA_ "GenSigCycleTimeActive" SG_ 1033 PCUSWNotReady 100;
BA_ "GenSigCycleTime" SG_ 1033 VCUSWNotReady 500;
BA_ "GenSigCycleTimeActive" SG_ 1033 VCUSWNotReady 100;
BA_ "GenSigCycleTime" SG_ 1033 HVRequestOC 500;
BA_ "GenSigCycleTimeActive" SG_ 1033 HVRequestOC 100;
BA_ "GenSigCycleTime" SG_ 1035 CondensorFanPWMHigh 500;
BA_ "GenSigCycleTimeActive" SG_ 1035 CondensorFanPWMHigh 500;
BA_ "GenSigCycleTime" SG_ 1035 ACPressureSupplyError 500;
BA_ "GenSigCycleTimeActive" SG_ 1035 ACPressureSupplyError 500;
BA_ "GenSigCycleTime" SG_ 1035 InverterActualRpm 500;
BA_ "GenSigCycleTimeActive" SG_ 1035 InverterActualRpm 500;
BA_ "GenSigCycleTime" SG_ 1035 ACElectricalPower 500;
BA_ "GenSigCycleTimeActive" SG_ 1035 ACElectricalPower 500;
BA_ "GenSigCycleTime" SG_ 1035 FluidHeaterOldError 500;
BA_ "GenSigCycleTimeActive" SG_ 1035 FluidHeaterOldError 500;
BA_ "GenSigCycleTime" SG_ 1035 ACPressure 500;
BA_ "GenSigCycleTimeActive" SG_ 1035 ACPressure 500;
BA_ "GenSigCycleTime" SG_ 1035 CondensorFanPeriod 500;
BA_ "GenSigCycleTimeActive" SG_ 1035 CondensorFanPeriod 500;
BA_ "GenSigCycleTime" SG_ 1035 InverterSetRpm 500;
BA_ "GenSigCycleTimeActive" SG_ 1035 InverterSetRpm 500;
BA_ "GenSigCycleTime" SG_ 1035 CompartmentFanSpeed 500;
BA_ "GenSigCycleTimeActive" SG_ 1035 CompartmentFanSpeed 500;
BA_ "GenSigCycleTime" SG_ 1035 FluidHeaterCurrentError 500;
BA_ "GenSigCycleTimeActive" SG_ 1035 FluidHeaterCurrentError 500;
BA_ "GenSigCycleTime" SG_ 774 BatteryLinearAge 1000;
BA_ "GenSigCycleTimeActive" SG_ 774 BatteryLinearAge 1000;
BA_ "GenSigCycleTime" SG_ 774 RelativeEnergyContent 1000;
BA_ "GenSigCycleTimeActive" SG_ 774 RelativeEnergyContent 1000;
BA_ "GenSigCycleTime" SG_ 774 EquivalentInternalResistance 1000;
BA_ "GenSigCycleTimeActive" SG_ 774 EquivalentInternalResistance 1000;
BA_ "GenSigCycleTime" SG_ 773 sys_intIsoError 200;
BA_ "GenSigCycleTimeActive" SG_ 773 sys_intIsoError 200;
BA_ "GenSigCycleTime" SG_ 773 Charge_Overcurrent 200;
BA_ "GenSigCycleTimeActive" SG_ 773 Charge_Overcurrent 200;
BA_ "GenSigCycleTime" SG_ 773 sys_BMI_state 200;
BA_ "GenSigCycleTimeActive" SG_ 773 sys_BMI_state 200;
BA_ "GenSigCycleTime" SG_ 773 Battery_Type 200;
BA_ "GenSigCycleTimeActive" SG_ 773 Battery_Type 200;
BA_ "GenSigCycleTime" SG_ 773 BatteryChargeEN 200;
BA_ "GenSigCycleTimeActive" SG_ 773 BatteryChargeEN 200;
BA_ "GenSigCycleTime" SG_ 773 Charger_PWM_Cmd 200;
BA_ "GenSigCycleTimeActive" SG_ 773 Charger_PWM_Cmd 200;
BA_ "GenSigCycleTime" SG_ 773 Waiting_OK_Temp_Discharge 200;
BA_ "GenSigCycleTimeActive" SG_ 773 Waiting_OK_Temp_Discharge 200;
BA_ "GenSigCycleTime" SG_ 773 sys_extIsoError 200;
BA_ "GenSigCycleTimeActive" SG_ 773 sys_extIsoError 200;
BA_ "GenSigCycleTime" SG_ 773 BMSPTCReady 200;
BA_ "GenSigCycleTimeActive" SG_ 773 BMSPTCReady 200;
BA_ "GenSigCycleTime" SG_ 773 sys_BMITempError 200;
BA_ "GenSigCycleTimeActive" SG_ 773 sys_BMITempError 200;
BA_ "GenSigCycleTime" SG_ 773 No_Charge_Current 200;
BA_ "GenSigCycleTimeActive" SG_ 773 No_Charge_Current 200;
BA_ "GenSigCycleTime" SG_ 773 Charge_Interrupt 200;
BA_ "GenSigCycleTimeActive" SG_ 773 Charge_Interrupt 200;
BA_ "GenSigCycleTime" SG_ 773 Charge_Overvoltage 200;
BA_ "GenSigCycleTimeActive" SG_ 773 Charge_Overvoltage 200;
BA_ "GenSigCycleTime" SG_ 773 sys_thermalIsoError 200;
BA_ "GenSigCycleTimeActive" SG_ 773 sys_thermalIsoError 200;
BA_ "GenSigCycleTime" SG_ 773 SOCAdaptationOutOfRange 200;
BA_ "GenSigCycleTimeActive" SG_ 773 SOCAdaptationOutOfRange 200;
BA_ "GenSigCycleTime" SG_ 773 sys_ZebraTempError 200;
BA_ "GenSigCycleTimeActive" SG_ 773 sys_ZebraTempError 200;
BA_ "GenSigCycleTime" SG_ 772 AC_Heater_Relay_Status 200;
BA_ "GenSigCycleTimeActive" SG_ 772 AC_Heater_Relay_Status 200;
BA_ "GenSigCycleTime" SG_ 772 Too_Many_Failed_Cells 200;
BA_ "GenSigCycleTimeActive" SG_ 772 Too_Many_Failed_Cells 200;
BA_ "GenSigCycleTime" SG_ 772 sys_EOC 200;
BA_ "GenSigCycleTimeActive" SG_ 772 sys_EOC 200;
BA_ "GenSigCycleTime" SG_ 772 Waiting_OK_Temp_Charge 200;
BA_ "GenSigCycleTimeActive" SG_ 772 Waiting_OK_Temp_Charge 200;
BA_ "GenSigCycleTime" SG_ 772 sys_highestErrCat 200;
BA_ "GenSigCycleTimeActive" SG_ 772 sys_highestErrCat 200;
BA_ "GenSigCycleTime" SG_ 772 Reach_EOC_please 200;
BA_ "GenSigCycleTimeActive" SG_ 772 Reach_EOC_please 200;
BA_ "GenSigCycleTime" SG_ 772 AC_Heater_Switch_Status 200;
BA_ "GenSigCycleTimeActive" SG_ 772 AC_Heater_Switch_Status 200;
BA_ "GenSigCycleTime" SG_ 771 sys_dischargeEN 200;
BA_ "GenSigCycleTimeActive" SG_ 771 sys_dischargeEN 200;
BA_ "GenSigCycleTime" SG_ 771 sys_currentMaxCharge 200;
BA_ "GenSigCycleTimeActive" SG_ 771 sys_currentMaxCharge 200;
BA_ "GenSigCycleTime" SG_ 771 sys_emergency 200;
BA_ "GenSigCycleTimeActive" SG_ 771 sys_emergency 200;
BA_ "GenSigCycleTime" SG_ 771 sys_fastchargeEN 200;
BA_ "GenSigCycleTimeActive" SG_ 771 sys_fastchargeEN 200;
BA_ "GenSigCycleTime" SG_ 771 sys_regenBrakingEN 200;
BA_ "GenSigCycleTimeActive" SG_ 771 sys_regenBrakingEN 200;
BA_ "GenSigCycleTime" SG_ 771 sys_crash 200;
BA_ "GenSigCycleTimeActive" SG_ 771 sys_crash 200;
BA_ "GenSigCycleTime" SG_ 771 sys_fan_status 200;
BA_ "GenSigCycleTimeActive" SG_ 771 sys_fan_status 200;
BA_ "GenSigCycleTime" SG_ 771 sys_SOCGreater102 200;
BA_ "GenSigCycleTimeActive" SG_ 771 sys_SOCGreater102 200;
BA_ "GenSigCycleTime" SG_ 771 sys_waiting_temp_err 200;
BA_ "GenSigCycleTimeActive" SG_ 771 sys_waiting_temp_err 200;
BA_ "GenSigCycleTime" SG_ 771 sys_voltageMaxCharge 200;
BA_ "GenSigCycleTimeActive" SG_ 771 sys_voltageMaxCharge 200;
BA_ "GenSigCycleTime" SG_ 770 sys_currentMaxDischarge 200;
BA_ "GenSigCycleTimeActive" SG_ 770 sys_currentMaxDischarge 200;
BA_ "GenSigCycleTime" SG_ 770 sys_isoerror 200;
BA_ "GenSigCycleTimeActive" SG_ 770 sys_isoerror 200;
BA_ "GenSigCycleTime" SG_ 770 sys_voltageMinDischarge 200;
BA_ "GenSigCycleTimeActive" SG_ 770 sys_voltageMinDischarge 200;
BA_ "GenSigCycleTime" SG_ 770 sys_errGeneral 200;
BA_ "GenSigCycleTimeActive" SG_ 770 sys_errGeneral 200;
BA_ "GenSigCycleTime" SG_ 769 sys_current 200;
BA_ "GenSigCycleTimeActive" SG_ 769 sys_current 200;
BA_ "GenSigCycleTime" SG_ 769 sys_dod 200;
BA_ "GenSigCycleTimeActive" SG_ 769 sys_dod 200;
BA_ "GenSigCycleTime" SG_ 769 sys_tempMean 200;
BA_ "GenSigCycleTimeActive" SG_ 769 sys_tempMean 200;
BA_ "GenSigCycleTime" SG_ 769 sys_voltage 200;
BA_ "GenSigCycleTimeActive" SG_ 769 sys_voltage 200;
BA_ "GenSigCycleTime" SG_ 778 sys_ignition 100;
BA_ "GenSigCycleTimeActive" SG_ 778 sys_ignition 100;
BA_ "GenSigCycleTime" SG_ 778 sys_cumCapacity285_310 100;
BA_ "GenSigCycleTimeActive" SG_ 778 sys_cumCapacity285_310 100;
BA_ "GenSigCycleTime" SG_ 778 BatterySOC 100;
BA_ "GenSigCycleTimeActive" SG_ 778 BatterySOC 100;
BA_ "GenSigCycleTime" SG_ 778 sys_cumCapacity270_285 100;
BA_ "GenSigCycleTimeActive" SG_ 778 sys_cumCapacity270_285 100;
BA_ "GenSigCycleTime" SG_ 777 sys_numberSOC_10 30000;
BA_ "GenSigCycleTimeActive" SG_ 777 sys_numberSOC_10 30000;
BA_ "GenSigCycleTime" SG_ 777 sys_minimumISOResistance 30000;
BA_ "GenSigCycleTimeActive" SG_ 777 sys_minimumISOResistance 30000;
BA_ "GenSigCycleTime" SG_ 777 sys_numberSOC_3 30000;
BA_ "GenSigCycleTimeActive" SG_ 777 sys_numberSOC_3 30000;
BA_ "GenSigCycleTime" SG_ 777 sys_numberSOC_20 30000;
BA_ "GenSigCycleTimeActive" SG_ 777 sys_numberSOC_20 30000;
BA_ "GenSigCycleTime" SG_ 776 sys_numberOfEOC 30000;
BA_ "GenSigCycleTimeActive" SG_ 776 sys_numberOfEOC 30000;
BA_ "GenSigCycleTime" SG_ 776 sys_cumOperatingTime 30000;
BA_ "GenSigCycleTimeActive" SG_ 776 sys_cumOperatingTime 30000;
BA_ "GenSigCycleTime" SG_ 776 sys_numberOfRegenBreaking 30000;
BA_ "GenSigCycleTimeActive" SG_ 776 sys_numberOfRegenBreaking 30000;
BA_ "GenSigCycleTime" SG_ 776 sys_ratedCycles 30000;
BA_ "GenSigCycleTimeActive" SG_ 776 sys_ratedCycles 30000;
BA_ "GenSigCycleTime" SG_ 775 sys_batteryType 30000;
BA_ "GenSigCycleTimeActive" SG_ 775 sys_batteryType 100;
BA_ "GenSigCycleTime" SG_ 775 sys_batterySN 30000;
BA_ "GenSigCycleTimeActive" SG_ 775 sys_batterySN 100;
BA_ "GenSigCycleTime" SG_ 775 sys_numberFailedCells 30000;
BA_ "GenSigCycleTimeActive" SG_ 775 sys_numberFailedCells 100;
BA_ "GenSigCycleTime" SG_ 768 BMI_Init_Successful 1000;
BA_ "GenSigCycleTimeActive" SG_ 768 BMI_Init_Successful 1000;
BA_ "GenSigCycleTime" SG_ 768 BMSHardwareTag 1000;
BA_ "GenSigCycleTimeActive" SG_ 768 BMSHardwareTag 1000;
BA_ "GenSigCycleTime" SG_ 768 BMSSoftwareTag 1000;
BA_ "GenSigCycleTimeActive" SG_ 768 BMSSoftwareTag 1000;
BA_ "GenSigCycleTime" SG_ 783 BatterySerialNumber2 30000;
BA_ "GenSigCycleTimeActive" SG_ 783 BatterySerialNumber2 100;
BA_ "GenSigCycleTime" SG_ 782 BatterySerialNumber1 30000;
BA_ "GenSigCycleTimeActive" SG_ 782 BatterySerialNumber1 100;
BA_ "GenSigCycleTime" SG_ 1200 RearRightWheelSpeed 14;
BA_ "GenSigCycleTimeActive" SG_ 1200 RearRightWheelSpeed 14;
BA_ "GenSigStartValue" SG_ 1200 RearRightWheelSpeed 10000;
BA_ "GenSigCycleTime" SG_ 1200 FrontLeftWheelSpeed 14;
BA_ "GenSigCycleTimeActive" SG_ 1200 FrontLeftWheelSpeed 14;
BA_ "GenSigStartValue" SG_ 1200 FrontLeftWheelSpeed 10000;
BA_ "GenSigCycleTime" SG_ 1200 RearLeftWheelSpeed 14;
BA_ "GenSigCycleTimeActive" SG_ 1200 RearLeftWheelSpeed 14;
BA_ "GenSigStartValue" SG_ 1200 RearLeftWheelSpeed 10000;
BA_ "GenSigCycleTime" SG_ 1200 FrontRightWheelSpeed 14;
BA_ "GenSigCycleTimeActive" SG_ 1200 FrontRightWheelSpeed 14;
BA_ "GenSigStartValue" SG_ 1200 FrontRightWheelSpeed 10000;
BA_ "GenSigCycleTime" SG_ 528 EBDFailed 14;
BA_ "GenSigCycleTimeActive" SG_ 528 EBDFailed 14;
BA_ "GenSigCycleTime" SG_ 528 ABSEvent 14;
BA_ "GenSigCycleTimeActive" SG_ 528 ABSEvent 14;
BA_ "GenSigCycleTime" SG_ 528 ABSFailed 14;
BA_ "GenSigCycleTimeActive" SG_ 528 ABSFailed 14;
BA_ "GenSigCycleTime" SG_ 528 DirectionalWheelSpeedSensing 14;
BA_ "GenSigCycleTimeActive" SG_ 528 DirectionalWheelSpeedSensing 14;
BA_ "GenSigCycleTime" SG_ 528 PCMTyreUsedInCalc 14;
BA_ "GenSigCycleTimeActive" SG_ 528 PCMTyreUsedInCalc 14;
BA_ "GenSigCycleTime" SG_ 528 Brake1Counter 14;
BA_ "GenSigCycleTimeActive" SG_ 528 Brake1Counter 14;
VAL_ 1120 RIL_Request 3 "RIL Requested On" 2 "RIL Requested Plant Mode" 1 "Reserved" 0 "RIL Requested Off" ;
VAL_ 35 RCM_FuelCutOff 2 "Normal Operation" 1 "Terminate Fuel" 0 "Invalid" ;
VAL_ 35 RCM_EventNotification 1 "Airbag Deployed" 0 "Inactive" ;
VAL_ 1874 VIN_Index 3 "Third PArt of VIN number" 2 "Second part of VIN number" 1 "First part of VIN number" 0 "Invalid" ;
VAL_ 1027 TimeMonth 11 "December" 10 "November" 9 "October" 8 "September" 7 "August" 6 "July" 5 "June" 4 "May" 3 "April" 2 "March" 1 "February" 0 "January" ;
VAL_ 1027 TimeDayInWeek 6 "Saturday" 5 "Friday" 4 "Thursday" 3 "Wednesday" 2 "Tuesday" 1 "Monday" 0 "Sunday" ;
VAL_ 1025 MemoryManagementStatus 1 "Lock" 0 "Free" ;
VAL_ 1025 AirbagLampDriver 3 "Lamptest" 2 "RCM timeout" 1 "RCM command" 0 "Reserved" ;
VAL_ 1025 HelpDeskLampStatus 4 "Blinking 2Hz Error" 3 "Blinking 2Hz" 2 "Blinking 0.5Hz" 1 "On" 0 "Off" ;
VAL_ 1025 PhoneCallStatus 4 "Reserved" 3 "In call" 2 "Incoming call" 1 "Calling" 0 "No call" ;
VAL_ 1025 GPRSStatus 5 "Registered, roaming" 3 "Registration denied" 2 "Not registered" 1 "Registered" 0 "Not registered, not searching" ;
VAL_ 1025 InCommunication 1 "Communicating via GPRS" 0 "Not communicating via GPRS" ;
VAL_ 1025 GPSAntennaStatus 2 "Short detected" 1 "OK" 0 "Open detected" ;
VAL_ 1025 CarState 2 "Charge" 1 "Discharge" 0 "Park" ;
VAL_ 1025 BluetoothConnection 1 "Connected to 1 device" 0 "Not connected" ;
VAL_ 1025 BluetoothStatus 1 "On and ready" 0 "Not available or Off" ;
VAL_ 1025 GPSStatus 15 "Not allowed by user in maintenance server" 11 "Only 3 usable satellites" 10 "Only 2 usable satellites" 9 "Only 1 usable satellite" 8 "No usable satellites" 3 "PDOP is too high" 1 "Doing position fixes" 0 "GPS Time not received yet" ;
VAL_ 1025 ContactKey 1 "Key Run active" 0 "Key Run not active" ;
VAL_ 1025 SIMCardStatus 1 "OK" 0 "Not inserted or PIN error" ;
VAL_ 1025 HelpDeskRequest 1 "Request" 0 "No request" ;
VAL_ 1025 GSMStatus 5 "Registered, roaming" 3 "Registration denied" 2 "Not registered" 1 "Registered" 0 "Not registered, not searching" ;
VAL_ 1025 GPSModuleStatus 3 "Error" 2 "starting / Waking Up" 1 "Ready" 0 "Off / Asleep" ;
VAL_ 1025 CSQQuality 31 "-51dBm or greater" 30 "-53dBm" 29 "-55dBm" 28 "-57dBm" 27 "-59dBm" 26 "-61dBm" 25 "-63dBm" 24 "-65dBm" 23 "-67dBm" 22 "-69dBm" 21 "-71dBm" 20 "-73dBm" 19 "-75dBm" 18 "-77dBm" 17 "-79dBm" 16 "-81dBm" 15 "-83dBm" 14 "-85dBm" 13 "-87dBm" 12 "-89dBm" 11 "-91dBm" 10 "-93dBm" 9 "-95dBm" 8 "-97dBm" 7 "-99dBm" 6 "-101dBm" 5 "-103dBm" 4 "-105dBm" 3 "-107dBm" 2 "-109dBm" 1 "-111dBm" 0 "-113dBm or less" ;
VAL_ 1025 ConnectedToServer 1 "Connected" 0 "Not connected" ;
VAL_ 1025 AirbagLampStatus 3 "On" 2 "Blinking (5Hz)" 0 "Off" ;
VAL_ 1025 HelpDeskButtonStatus 1 "Pushed" 0 "Not pushed" ;
VAL_ 1025 GSMModuleStatus 3 "Error" 2 "starting / Waking Up" 1 "Ready" 0 "Off / Asleep" ;
VAL_ 1025 AssistNumberProgrammed 1 "Programmed" 0 "Not programmed" ;
VAL_ 1025 EPOStatus 1 "On" 0 "Off" ;
VAL_ 1025 CrashEvent 1 "Airbag deployed" 0 "No event" ;
VAL_ 1026 CarSharingButtonStatus 1 "Pushed" 0 "Not pushed" ;
VAL_ 1026 CarSharingAntitheft 1 "Enabled, car is not able to start" 0 "Disabled, car is possible to start" ;
VAL_ 1026 CarSharingMode 3 "Maintenance" 2 "Manager" 1 "Normal" 0 "Test" ;
VAL_ 1026 CarSharingState 6 "Wait close" 5 "Running" 4 "Try to start" 3 "Waiting driver" 2 "Ready" 1 "Waiting begin time" 0 "Free" ;
VAL_ 1026 CarSharingLEDStatus 2 "Late" 1 "Reservation" 0 "Free, end request" ;
VAL_ 785 FastChargeRequest 1 "Fast charge request" 0 "No fast charge request" ;
VAL_ 785 BatteryChargeRequest 1 "Battery charge requested" 0 "Battery charge not requested" ;
VAL_ 514 BrakeLightSwitch 1 "Active" 0 "Not active" ;
VAL_ 514 MotorTorqueInsDenied 1 "Requested ESP torque is out of motor capacity" 0 "Motor torque controlled by DTR or ESP" ;
VAL_ 784 TIM_Status 1 "TIM enabled" 0 "TIM disabled" ;
VAL_ 784 Charger_Status 1 "Charge enabled" 0 "Charge disabled" ;
VAL_ 784 DC_DC_Status 1 "DC-DC Enabled" 0 "DC-DC disabled" ;
VAL_ 784 PCU_Fault 1 "PCU detected an error" 0 "PCU OK" ;
VAL_ 784 BroadcastMode 1 "Broadcast Mode" 0 "Request Mode" ;
VAL_ 612 PASEnable 1 "Power allowed to PAS" 0 "No power allowed to PAS" ;
VAL_ 612 ESPIndication 3 "Light Flashing Fast" 2 "Light Flashing Slow" 1 "Light On" 0 "Light Off" ;
VAL_ 612 PowerLimitIndication 3 "Light Flashing Fast" 2 "Light Flashing Slow" 1 "Light On" 0 "Light Off" ;
VAL_ 612 EconomyIndication 3 "Light Flashing Fast" 2 "Light Flashing Slow" 1 "Light On" 0 "Light Off" ;
VAL_ 612 ABSWarningIndication 3 "Light Flashing Fast" 2 "Light Flashing Slow" 1 "Light On" 0 "Light Off" ;
VAL_ 612 ElectricHzIndication 3 "Light Flashing Fast" 2 "Light Flashing Slow" 1 "Light On" 0 "Light Off" ;
VAL_ 612 BrakeWarningIndication 3 "Light Flashing Fast" 2 "Light Flashing Slow" 1 "Light On" 0 "Light Off" ;
VAL_ 612 OvertempIndication 3 "Light Flashing Fast" 2 "Light Flashing Slow" 1 "Light On" 0 "Light Off" ;
VAL_ 612 NeutralIndication 3 "Light Flashing Fast" 2 "Light Flashing Slow" 1 "Light On" 0 "Light Off" ;
VAL_ 612 MILIndication 3 "Light Flashing Fast" 2 "Light Flashing Slow" 1 "Light On" 0 "Light Off" ;
VAL_ 612 PowertrainGeneration 3 "Gen 4" 2 "Gen 3" 1 "Gen 2" 0 "Gen 1" ;
VAL_ 612 ChargingIndication 3 "Light Flashing Fast" 2 "Light Flashing Slow" 1 "Light On" 0 "Light Off" ;
VAL_ 612 AuxiliaryBatteryLowIndication 3 "Light Flashing Fast" 2 "Light Flashing Slow" 1 "Light On" 0 "Light Off" ;
VAL_ 612 DriveEnableIndication 3 "Light Flashing Fast" 2 "Light Flashing Slow" 1 "Light On" 0 "Light Off" ;
VAL_ 612 OnPlugIndication 3 "Light Flashing Fast" 2 "Light Flashing Slow" 1 "Light On" 0 "Light Off" ;
VAL_ 612 GearPosition 7 "Fault" 4 "Economy" 3 "Drive" 2 "Neutral" 1 "Reverse" 0 "Park" ;
VAL_ 612 ParkIndication 3 "Light Flashing Fast" 2 "Light Flashing Slow" 1 "Light On" 0 "Light Off" ;
VAL_ 612 ReverseIndication 3 "Light Flashing Fast" 2 "Light Flashing Slow" 1 "Light On" 0 "Light Off" ;
VAL_ 612 LowSOCIndication 3 "Light Flashing Fast" 2 "Light Flashing Slow" 1 "Light On" 0 "Light Off" ;
VAL_ 612 PilotSignalPresent 1 "Pilot signal is present and accepted" 0 "Pilot signal is not present and/or accepted" ;
VAL_ 612 DriveIndication 3 "Light Flashing Fast" 2 "Light Flashing Slow" 1 "Light On" 0 "Light Off" ;
VAL_ 593 SecurityIDActive 2 "Refused" 1 "Active" 0 "Not Active" ;
VAL_ 593 VehicleStatus 2 "Disabled" 1 "Enabled" 0 "Wait" ;
VAL_ 850 EnableCharger 1 "Description for the value '0x1'" 0 "Charger is not enabled" ;
VAL_ 1173 PAS_Status 1 "Error in PAS." 0 "OK" ;
VAL_ 391 SASState 1 "SAS signals healthy" 0 "SAS signal error" ;
VAL_ 391 SASCal 1 "SAS calibrated" 0 "SAS NOT calibrated" ;
VAL_ 391 SASTrim 1 "SAS Trim" 0 "SAS NOT Trim" ;
VAL_ 390 ESPSystemStatus 3 "Incomplete startup" 2 "Siagnostic session active" 1 "ESP system error" 0 "ESP system operational" ;
VAL_ 390 EBDStatus 1 "EBD error" 0 "EBD operational" ;
VAL_ 390 ESPStatus 1 "ESP error" 0 "ESP operational" ;
VAL_ 390 ABSStatus 1 "ABS error" 0 "ABS operational" ;
VAL_ 390 ESPLamp 3 "Light flash fast (2Hz)" 2 "Light flash slow (0.5Hz)" 1 "Light On" 0 "Light Off" ;
VAL_ 390 ESPTorqueIntervention 1 "Intervention" 0 "No intervention" ;
VAL_ 390 ABSLamp 3 "Light flash fast (2Hz)" 2 "Light flash slow (0.5Hz)" 1 "Light On" 0 "Light Off" ;
VAL_ 390 EBDLamp 3 "Light flash fast (2Hz)" 2 "Light flash slow (0.5Hz)" 1 "Light On" 0 "Light Off" ;
VAL_ 851 ChargerStatus 4 "Non-Recoverable Error" 3 "Recoverable Error" 2 "Charge" 1 "Ready" ;
VAL_ 853 CommunicationFailure 1 "Error present" 0 "Error not present" ;
VAL_ 853 LowMainsError 1 "Error present" 0 "Error not present" ;
VAL_ 853 DCUndervoltageError 1 "Error present" 0 "Error not present" ;
VAL_ 853 CurrentLimitError 1 "Error present" 0 "Error not present" ;
VAL_ 853 HighTemperatureShutdownError 1 "Error present" 0 "Error not present" ;
VAL_ 853 HighMainsError 1 "Error present" 0 "Error not present" ;
VAL_ 853 DCOvervoltageError 1 "Error present" 0 "Error not present" ;
VAL_ 853 ControllerCommunicationError 1 "Error present" 0 "Error not present" ;
VAL_ 853 ModuleFailureError 1 "Error present" 0 "Error not present" ;
VAL_ 853 LowTemperatureShutdownError 1 "Error present" 0 "Error not present" ;
VAL_ 1032 ACPresent 1 "Description for the value '0x1'" 0 "AC not present" ;
VAL_ 1032 CDCMOperationState 5 "Charge" 4 "Limphome" 3 "Shutdown" 2 "Run" 1 "On" 0 "StartUp" ;
VAL_ 69 PTCFeedbackStatus 3 "Shorted or Open Line" 2 "Other Failure State" 1 "HV Missing" 0 "No Problem" ;
VAL_ 69 PTCControlStatus 6 "5 Elements ON" 5 "4 Elements ON" 4 "3 Elements ON" 3 "2 Elements ON" 2 "1 Element ON" 1 "Monitor HV" 0 "Off" ;
VAL_ 69 PTCHeaterStatus 1 "On" 0 "Off" ;
VAL_ 69 PTC_FuelCutOff 2 "Normal operation" 1 "Terminate Fuel" 0 "Communication broken with PTC" ;
VAL_ 1033 KnobPositionTooHigh 1 "Fault present" 0 "Fault not present" ;
VAL_ 1033 CondenserFanOC 1 "Fault present" 0 "Fault not present" ;
VAL_ 1033 RearDemistSC 1 "Fault present" 0 "Fault not present" ;
VAL_ 1033 HVrequestSC 1 "Fault present" 0 "Fault not present" ;
VAL_ 1033 FrontDemist2OC 1 "Fault present" 0 "Fault not present" ;
VAL_ 1033 ClimateCANTimeout 1 "Fault present" 0 "Fault not present" ;
VAL_ 1033 KnobPositionTooLow 1 "Fault present" 0 "Fault not present" ;
VAL_ 1033 HeaterEnableOC 1 "Fault present" 0 "Fault not present" ;
VAL_ 1033 HeaterEnableSC 1 "Fault present" 0 "Fault not present" ;
VAL_ 1033 CondenserFanSC 1 "Fault present" 0 "Fault not present" ;
VAL_ 1033 ForcedBlowerOC 1 "Fault present" 0 "Fault not present" ;
VAL_ 1033 InverterSupplyOC 1 "Fault present" 0 "Fault not present" ;
VAL_ 1033 FrontDemist1SC 1 "Fault present" 0 "Fault not present" ;
VAL_ 1033 ForcedBlowerSC 1 "Fault present" 0 "Fault not present" ;
VAL_ 1033 RearDemistOC 1 "Fault present" 0 "Fault not present" ;
VAL_ 1033 TemperatureSensorSignalTooLow 1 "Fault present" 0 "Fault not present" ;
VAL_ 1033 TemperatureSensorSignalTooHigh 1 "Fault present" 0 "Fault not present" ;
VAL_ 1033 InverterSupplySC 1 "Fault present" 0 "Fault not present" ;
VAL_ 1033 FrontDemist2SC 1 "Fault present" 0 "Fault not present" ;
VAL_ 1033 FrontDemist1OC 1 "Fault present" 0 "Fault not present" ;
VAL_ 1033 HVRequestOC 1 "Fault present" 0 "Fault not present" ;
VAL_ 773 sys_intIsoError 1 "Internal HV iso error detected" 0 "OK" ;
VAL_ 773 Charge_Overcurrent 1 "Charge current > max. battery charge current" 0 "OK" ;
VAL_ 773 sys_BMI_state 15 "Fault" 8 "PowerUp" 3 "Charge" 1 "Discharge" 0 "Park" ;
VAL_ 773 Battery_Type 3 "A123 Li-Ion" 2 "EnerDel Li-Ion" 1 "Z5" 0 "Z36" ;
VAL_ 773 BatteryChargeEN 1 "Battery contactors closed for charge" 0 "Battery contactors open." ;
VAL_ 773 Waiting_OK_Temp_Discharge 1 "Discharge delayed until correct Temp" 0 "No delay in discharge" ;
VAL_ 773 sys_extIsoError 1 "External HV iso error detected" 0 "OK" ;
VAL_ 773 sys_BMITempError 3 "BMS critical overtemp fault reached. Immediate shutdown" 2 "BMS overtemp level 2 reached." 1 "BMS overtemp level 1 reached." 0 "No error" ;
VAL_ 773 No_Charge_Current 1 "No charging current into battery" 0 "OK" ;
VAL_ 773 Charge_Interrupt 1 "Interrupt charging" 0 "Do not interrupt charging" ;
VAL_ 773 Charge_Overvoltage 1 "Charge voltage > max. battery charge current" 0 "OK" ;
VAL_ 773 sys_thermalIsoError 1 "Thermal iso error detected" 0 "OK" ;
VAL_ 773 SOCAdaptationOutOfRange 1 "Calculated SOC is out of range for autocalibration" 0 "No Error" ;
VAL_ 773 sys_ZebraTempError 3 "Battery pack critical overtemp reached. Immediate shutdown" 2 "Battery pack overtemp warning level 2 reached." 1 "Battery pack overtemp warning level 1 reached. Introducing LOS" 0 "No error" ;
VAL_ 772 AC_Heater_Relay_Status 1 "AC heater realay enabled" 0 "AC heater relay disabled" ;
VAL_ 772 Too_Many_Failed_Cells 1 "More than 10% failed cells" 0 "Less than 10% failed cells" ;
VAL_ 772 Waiting_OK_Temp_Charge 1 "Charge delayed until correct Temp" 0 "No delay in charge" ;
VAL_ 772 sys_highestErrCat 4 "Category switch-off" 3 "Category delayed switch-off" 2 "Category notice" 1 "RESERVED" 0 "No error" ;
VAL_ 772 Reach_EOC_please 1 "Battery needs to reach EOC" 0 "Invalid" ;
VAL_ 772 AC_Heater_Switch_Status 1 "AC heater switch closed" 0 "AC heater switch opened" ;
VAL_ 770 sys_isoerror 1 "Int. or Ext. ISO fault" ;
VAL_ 770 sys_errGeneral 1 "General error active" ;
VAL_ 768 BMI_Init_Successful 1 "Init OK, BMI ready" 0 "Error ocurred" ;
